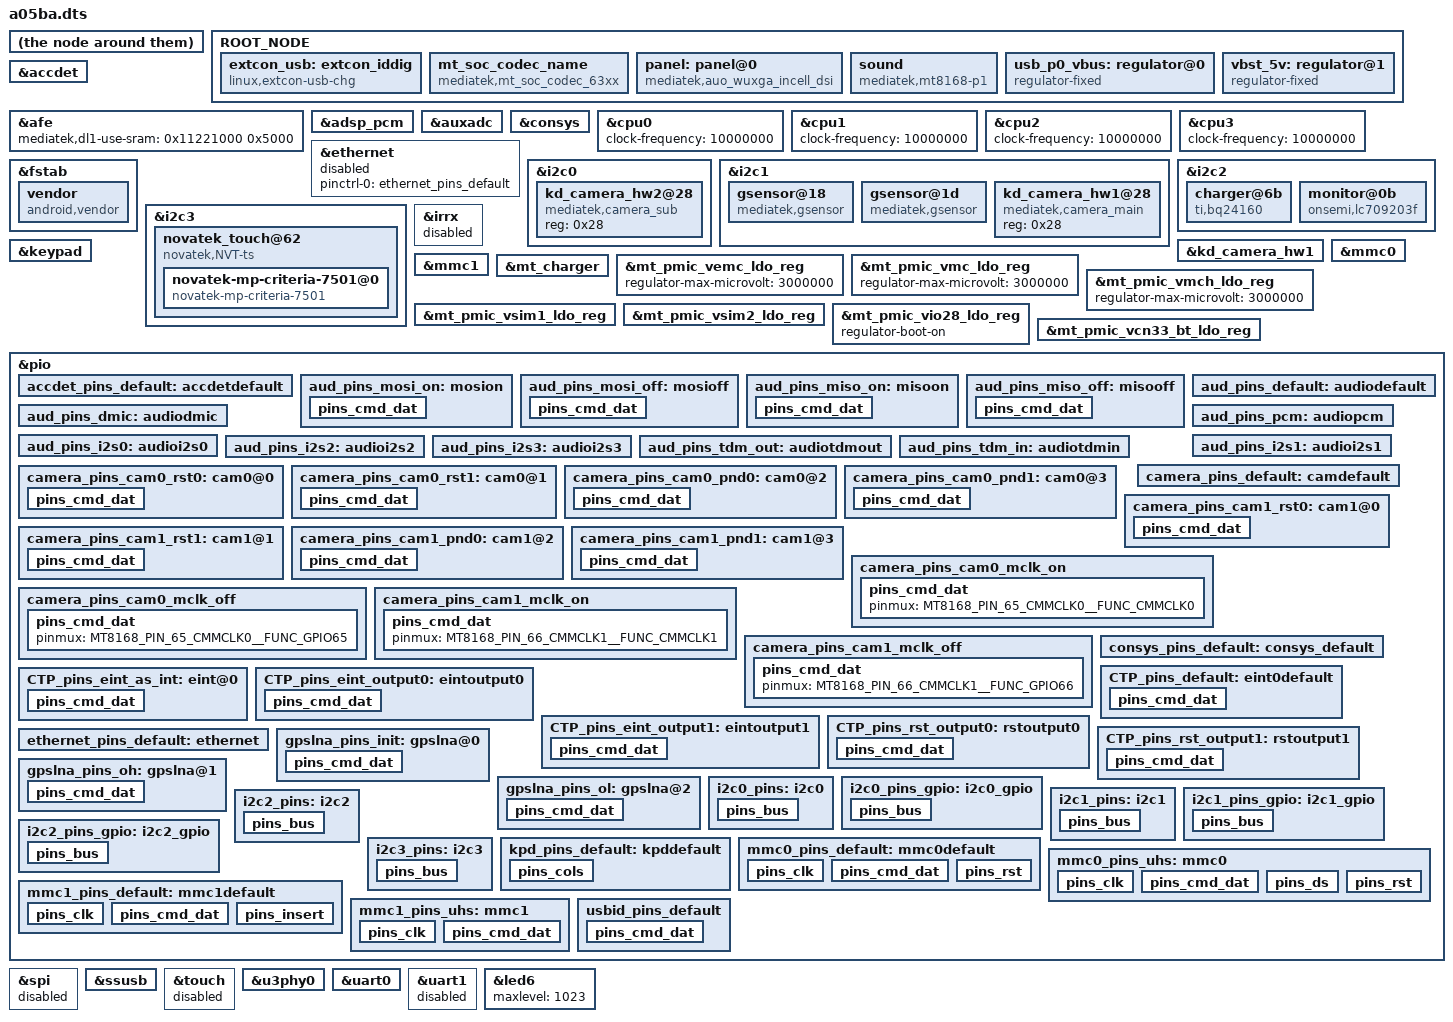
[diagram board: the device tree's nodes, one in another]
/*
 * Copyright (c) 2018 MediaTek Inc.
 *
 * This program is free software; you can redistribute it and/or modify
 * it under the terms of the GNU General Public License version 2 as
 * published by the Free Software Foundation.
 *
 * This program is distributed in the hope that it will be useful,
 * MERCHANTABILITY or FITNESS FOR A PARTICULAR PURPOSE.  See the
 * GNU General Public License for more details.
 */

#include <generated/autoconf.h>
/dts-v1/;

/plugin/;
#include <dt-bindings/clock/mt8168-clk.h>
#include <dt-bindings/interrupt-controller/irq.h>
#include <dt-bindings/interrupt-controller/arm-gic.h>
#include <dt-bindings/pinctrl/mt8168-pinfunc.h>
#include <dt-bindings/gpio/gpio.h>
#include <dt-bindings/phy/phy.h>
#define ROOT_NODE &odm

ROOT_NODE {
	extcon_usb: extcon_iddig {
		compatible = "linux,extcon-usb-chg";
		id-gpio = <&pio 17 GPIO_ACTIVE_HIGH>;
		pinctrl-names = "default";
		pinctrl-0 = <&usbid_pins_default>;
	};

	mt_soc_codec_name: mt_soc_codec_name {
		compatible = "mediatek,mt_soc_codec_63xx";
		use_hp_depop_flow = <0>; /* select 1: use, 0: not use */
		use_ul_260k = <0>; /* select 1: use, 0: not use */
	};

	panel: panel@0 {
		compatible = "mediatek,auo_wuxga_incell_dsi";
		gpio_lcd_rst = <&pio 20 0>;
		gpio_lcd_pwr = <&pio 127 0>;
		gpio_lcd_pwr2 = <&pio 122 0>;
		gpio_lcd_bl_en = <&pio 119 0>;
		reg-lcm-supply = <&mt_pmic_vsim1_ldo_reg>;
	};

	sound: sound {
		compatible = "mediatek,mt8168-p1";
		mediatek,platform = <&afe>;
		mediatek,adsp-platform = <&adsp_pcm>;
		pinctrl-names = "aud_mosi_on",
			"aud_mosi_off",
			"aud_miso_on",
			"aud_miso_off",
			"default",
			"aud_dmic",
			"aud_pcm",
			"aud_i2s0",
			"aud_i2s1",
			"aud_i2s2",
			"aud_i2s3",
			"aud_tdm_out",
			"aud_tdm_in";
		pinctrl-0 = <&aud_pins_mosi_on>;
		pinctrl-1 = <&aud_pins_mosi_off>;
		pinctrl-2 = <&aud_pins_miso_on>;
		pinctrl-3 = <&aud_pins_miso_off>;
		pinctrl-4 = <&aud_pins_default>;
		pinctrl-5 = <&aud_pins_dmic>;
		pinctrl-6 = <&aud_pins_pcm>;
		pinctrl-7 = <&aud_pins_i2s0>;
		pinctrl-8 = <&aud_pins_i2s1>;
		pinctrl-9 = <&aud_pins_i2s2>;
		pinctrl-10 = <&aud_pins_i2s3>;
		pinctrl-11 = <&aud_pins_tdm_out>;
		pinctrl-12 = <&aud_pins_tdm_in>;
		ext-amp1-gpio = <&pio 120 0>;
		ext-amp1en-gpio = <&pio 121 0>;
		/*ext-amp2-gpio = <&pio 69 0>;*/
		status = "okay";
	};

	usb_p0_vbus: regulator@0 {
		compatible = "regulator-fixed";
		regulator-name = "vbus";
		regulator-min-microvolt = <5000000>;
		regulator-max-microvolt = <5000000>;
		gpio = <&pio 16 GPIO_ACTIVE_HIGH>;
		enable-active-high;
	};

	vbst_5v: regulator@1 {
		compatible = "regulator-fixed";
		regulator-name = "vbst_5v";
		regulator-min-microvolt = <5000000>;
		regulator-max-microvolt = <5000000>;
		gpio = <&pio 18 GPIO_ACTIVE_HIGH>;
		enable-active-high;
	};
};

&accdet {
	accdet-mic-vol = <6>;
	headset-mode-setting = <0x500 0x500 1 0x1f0 0x800 0x800 0x20 0x44>;
	accdet-plugout-debounce = <1>;
	accdet-mic-mode = <1>;
	headset-eint-level-pol = <8>;
	/*headset-eint-level-pol = <4>;*/
	headset-three-key-threshold = <0 80 220 400>;
	headset-three-key-threshold-CDD = <0 121 192 600>;
	headset-four-key-threshold = <0 100 170 250 420>;
	pinctrl-names = "default", "state_eint_as_int";
	pinctrl-0 = <&accdet_pins_default>;
/*	pinctrl-1 = <&accdet_pins_eint_as_int>;*/
	status = "okay";
};

&afe {
	mediatek,dl1-use-sram = <0x11221000 0x5000>;
	status = "okay";
};

&adsp_pcm {
	status = "okay";
};

&auxadc {
	status = "okay";
};

&consys {
	pinctrl-names = "default", "gps_lna_state_init",
			"gps_lna_state_oh", "gps_lna_state_ol";
	pinctrl-0 = <&consys_pins_default>;
	pinctrl-1 = <&gpslna_pins_init>;
	pinctrl-2 = <&gpslna_pins_oh>;
	pinctrl-3 = <&gpslna_pins_ol>;
	status = "okay";
};

&cpu0 {
	clock-frequency = <10000000>;
};

&cpu1 {
	clock-frequency = <10000000>;
};

&cpu2 {
	clock-frequency = <10000000>;
};

&cpu3 {
	clock-frequency = <10000000>;
};

&ethernet {
	status = "disabled";
	pinctrl-names = "default";
	pinctrl-0 = <&ethernet_pins_default>;
};

&fstab {
	vendor {
		compatible = "android,vendor";
		dev = "/dev/block/platform/soc/11230000.mmc/by-name/vendor";
		type = "ext4";
		mnt_flags = "ro";
		fsmgr_flags = "wait,avb";
	};
};

&i2c0 {
	pinctrl-names = "default","gpio";
	pinctrl-0 = <&i2c0_pins>;
	pinctrl-1 = <&i2c0_pins_gpio>;
	clock-frequency = <370000>;
	status = "okay";
	scl-gpio = <&pio 58 0>;
	sda-gpio = <&pio 57 0>;

	kd_camera_hw2@28 {
		compatible = "mediatek,camera_sub";
		#address-cells = <1>;
		#size-cells = <0>;
		reg = <0x28>;
	};
};

&i2c1 {
	pinctrl-names = "default","gpio";
	pinctrl-0 = <&i2c1_pins>;
	pinctrl-1 = <&i2c1_pins_gpio>;
	clock-frequency = <370000>;
	status = "okay";
	scl-gpio = <&pio 60 0>;
	sda-gpio = <&pio 59 0>;

	gsensor@18 {
		compatible = "mediatek,gsensor";
		#address-cells = <1>;
		#size-cells = <0>;
		reg = <0x18>;
		status = "okay";
		i2c_num = <1>;
		i2c_addr = <0x18 0 0 0>;
		direction = <3>;
		power_id = <0xffff>;
		power_vol = <0>;
		firlen = <0>;
		is_batch_supported = <0>;
	};

	gsensor@1d {
		compatible = "mediatek,gsensor";
		#address-cells = <1>;
		#size-cells = <0>;
		reg = <0x1d>;
		status = "okay";
		i2c_num = <1>;
		i2c_addr = <0x1d 0 0 0>;
		direction = <2>;
		power_id = <0xffff>;
		power_vol = <0>;
		firlen = <0>;
		is_batch_supported = <0>;
	};

	kd_camera_hw1@28 {
		compatible = "mediatek,camera_main";
		#address-cells = <1>;
		#size-cells = <0>;
		reg = <0x28>;
	};
};

&i2c2 {
	pinctrl-names = "default","gpio";
	pinctrl-0 = <&i2c2_pins>;
	pinctrl-1 = <&i2c2_pins_gpio>;
	clock-frequency = <370000>;
	status = "okay";
	scl-gpio = <&pio 62 0>;
	sda-gpio = <&pio 61 0>;

	charger@6b {
		compatible = "ti,bq24160";
		#address-cells = <1>;
		#size-cells = <0>;
		reg      = <0x6b>;
		ena-gpio = <&pio 125 0>;
		/*acdet-gpio = <&pio 39 0>;*/
		/*usbdet-gpio = <&pio 40 0>;*/
	};

	monitor@0b {
		compatible = "onsemi,lc709203f";
		#address-cells = <1>;
		#size-cells = <0>;
		reg      = <0x0b>;
		irq-gpio = <&pio 67 0>;
	};
};

&i2c3 {
	pinctrl-names = "default";
	pinctrl-0 = <&i2c3_pins>;
	clock-frequency = <370000>;
	status = "okay";

	novatek_touch@62 {
		compatible = "novatek,NVT-ts";
		#address-cells = <1>;
		#size-cells = <0>;
		reg = <0x62>;
		novatek,irq-gpio = <&pio 78 0>;
		novatek,pen-support;
		novatek,wgp-stylus;

		novatek,mp-support-dt;

		novatek-mp-criteria-7501@0 {
			#address-cells = <1>;
			#size-cells = <0>;
			compatible = "novatek-mp-criteria-7501";

			/* MP Config */
			IC_X_CFG_SIZE = <32>;
			IC_Y_CFG_SIZE = <48>;
			IC_KEY_CFG_SIZE = <4>;
			X_Channel = <32>;
			Y_Channel = <48>;
			AIN_X = <0 1 2 3 4 5 6 7 8 9 10 11 12 13 14 15 16 17 18 19 20 21 22 23 24 25 26 27 28 29 30 31>;
			AIN_Y = <0 1 2 3 4 5 6 7 8 9 10 11 12 13 14 15 16 17 18 19 20 21 22 23 24 25 26 27 28 29 30 31 32 33 34 35 36 37 38 39 40 41 42 43 44 45 46 47>;
			AIN_KEY = <0 1 2 0xFF>;

			/* MP Criteria */
			PS_Config_Lmt_Short_Rawdata_P = <
				14008	14008	14008	14008	14008	14008	14008	14008	14008	14008	14008	14008	14008	14008	14008	14008	14008	14008	14008	14008	14008	14008	14008	14008	14008	14008	14008	14008	14008	14008	14008	14008
				14008	14008	14008	14008	14008	14008	14008	14008	14008	14008	14008	14008	14008	14008	14008	14008	14008	14008	14008	14008	14008	14008	14008	14008	14008	14008	14008	14008	14008	14008	14008	14008
				14008	14008	14008	14008	14008	14008	14008	14008	14008	14008	14008	14008	14008	14008	14008	14008	14008	14008	14008	14008	14008	14008	14008	14008	14008	14008	14008	14008	14008	14008	14008	14008
				14008	14008	14008	14008	14008	14008	14008	14008	14008	14008	14008	14008	14008	14008	14008	14008	14008	14008	14008	14008	14008	14008	14008	14008	14008	14008	14008	14008	14008	14008	14008	14008
				14008	14008	14008	14008	14008	14008	14008	14008	14008	14008	14008	14008	14008	14008	14008	14008	14008	14008	14008	14008	14008	14008	14008	14008	14008	14008	14008	14008	14008	14008	14008	14008
				14008	14008	14008	14008	14008	14008	14008	14008	14008	14008	14008	14008	14008	14008	14008	14008	14008	14008	14008	14008	14008	14008	14008	14008	14008	14008	14008	14008	14008	14008	14008	14008
				14008	14008	14008	14008	14008	14008	14008	14008	14008	14008	14008	14008	14008	14008	14008	14008	14008	14008	14008	14008	14008	14008	14008	14008	14008	14008	14008	14008	14008	14008	14008	14008
				14008	14008	14008	14008	14008	14008	14008	14008	14008	14008	14008	14008	14008	14008	14008	14008	14008	14008	14008	14008	14008	14008	14008	14008	14008	14008	14008	14008	14008	14008	14008	14008
				14008	14008	14008	14008	14008	14008	14008	14008	14008	14008	14008	14008	14008	14008	14008	14008	14008	14008	14008	14008	14008	14008	14008	14008	14008	14008	14008	14008	14008	14008	14008	14008
				14008	14008	14008	14008	14008	14008	14008	14008	14008	14008	14008	14008	14008	14008	14008	14008	14008	14008	14008	14008	14008	14008	14008	14008	14008	14008	14008	14008	14008	14008	14008	14008
				14008	14008	14008	14008	14008	14008	14008	14008	14008	14008	14008	14008	14008	14008	14008	14008	14008	14008	14008	14008	14008	14008	14008	14008	14008	14008	14008	14008	14008	14008	14008	14008
				14008	14008	14008	14008	14008	14008	14008	14008	14008	14008	14008	14008	14008	14008	14008	14008	14008	14008	14008	14008	14008	14008	14008	14008	14008	14008	14008	14008	14008	14008	14008	14008
				14008	14008	14008	14008	14008	14008	14008	14008	14008	14008	14008	14008	14008	14008	14008	14008	14008	14008	14008	14008	14008	14008	14008	14008	14008	14008	14008	14008	14008	14008	14008	14008
				14008	14008	14008	14008	14008	14008	14008	14008	14008	14008	14008	14008	14008	14008	14008	14008	14008	14008	14008	14008	14008	14008	14008	14008	14008	14008	14008	14008	14008	14008	14008	14008
				14008	14008	14008	14008	14008	14008	14008	14008	14008	14008	14008	14008	14008	14008	14008	14008	14008	14008	14008	14008	14008	14008	14008	14008	14008	14008	14008	14008	14008	14008	14008	14008
				14008	14008	14008	14008	14008	14008	14008	14008	14008	14008	14008	14008	14008	14008	14008	14008	14008	14008	14008	14008	14008	14008	14008	14008	14008	14008	14008	14008	14008	14008	14008	14008
				14008	14008	14008	14008	14008	14008	14008	14008	14008	14008	14008	14008	14008	14008	14008	14008	14008	14008	14008	14008	14008	14008	14008	14008	14008	14008	14008	14008	14008	14008	14008	14008
				14008	14008	14008	14008	14008	14008	14008	14008	14008	14008	14008	14008	14008	14008	14008	14008	14008	14008	14008	14008	14008	14008	14008	14008	14008	14008	14008	14008	14008	14008	14008	14008
				14008	14008	14008	14008	14008	14008	14008	14008	14008	14008	14008	14008	14008	14008	14008	14008	14008	14008	14008	14008	14008	14008	14008	14008	14008	14008	14008	14008	14008	14008	14008	14008
				14008	14008	14008	14008	14008	14008	14008	14008	14008	14008	14008	14008	14008	14008	14008	14008	14008	14008	14008	14008	14008	14008	14008	14008	14008	14008	14008	14008	14008	14008	14008	14008
				14008	14008	14008	14008	14008	14008	14008	14008	14008	14008	14008	14008	14008	14008	14008	14008	14008	14008	14008	14008	14008	14008	14008	14008	14008	14008	14008	14008	14008	14008	14008	14008
				14008	14008	14008	14008	14008	14008	14008	14008	14008	14008	14008	14008	14008	14008	14008	14008	14008	14008	14008	14008	14008	14008	14008	14008	14008	14008	14008	14008	14008	14008	14008	14008
				14008	14008	14008	14008	14008	14008	14008	14008	14008	14008	14008	14008	14008	14008	14008	14008	14008	14008	14008	14008	14008	14008	14008	14008	14008	14008	14008	14008	14008	14008	14008	14008
				14008	14008	14008	14008	14008	14008	14008	14008	14008	14008	14008	14008	14008	14008	14008	14008	14008	14008	14008	14008	14008	14008	14008	14008	14008	14008	14008	14008	14008	14008	14008	14008
				14008	14008	14008	14008	14008	14008	14008	14008	14008	14008	14008	14008	14008	14008	14008	14008	14008	14008	14008	14008	14008	14008	14008	14008	14008	14008	14008	14008	14008	14008	14008	14008
				14008	14008	14008	14008	14008	14008	14008	14008	14008	14008	14008	14008	14008	14008	14008	14008	14008	14008	14008	14008	14008	14008	14008	14008	14008	14008	14008	14008	14008	14008	14008	14008
				14008	14008	14008	14008	14008	14008	14008	14008	14008	14008	14008	14008	14008	14008	14008	14008	14008	14008	14008	14008	14008	14008	14008	14008	14008	14008	14008	14008	14008	14008	14008	14008
				14008	14008	14008	14008	14008	14008	14008	14008	14008	14008	14008	14008	14008	14008	14008	14008	14008	14008	14008	14008	14008	14008	14008	14008	14008	14008	14008	14008	14008	14008	14008	14008
				14008	14008	14008	14008	14008	14008	14008	14008	14008	14008	14008	14008	14008	14008	14008	14008	14008	14008	14008	14008	14008	14008	14008	14008	14008	14008	14008	14008	14008	14008	14008	14008
				14008	14008	14008	14008	14008	14008	14008	14008	14008	14008	14008	14008	14008	14008	14008	14008	14008	14008	14008	14008	14008	14008	14008	14008	14008	14008	14008	14008	14008	14008	14008	14008
				14008	14008	14008	14008	14008	14008	14008	14008	14008	14008	14008	14008	14008	14008	14008	14008	14008	14008	14008	14008	14008	14008	14008	14008	14008	14008	14008	14008	14008	14008	14008	14008
				14008	14008	14008	14008	14008	14008	14008	14008	14008	14008	14008	14008	14008	14008	14008	14008	14008	14008	14008	14008	14008	14008	14008	14008	14008	14008	14008	14008	14008	14008	14008	14008
				14008	14008	14008	14008	14008	14008	14008	14008	14008	14008	14008	14008	14008	14008	14008	14008	14008	14008	14008	14008	14008	14008	14008	14008	14008	14008	14008	14008	14008	14008	14008	14008
				14008	14008	14008	14008	14008	14008	14008	14008	14008	14008	14008	14008	14008	14008	14008	14008	14008	14008	14008	14008	14008	14008	14008	14008	14008	14008	14008	14008	14008	14008	14008	14008
				14008	14008	14008	14008	14008	14008	14008	14008	14008	14008	14008	14008	14008	14008	14008	14008	14008	14008	14008	14008	14008	14008	14008	14008	14008	14008	14008	14008	14008	14008	14008	14008
				14008	14008	14008	14008	14008	14008	14008	14008	14008	14008	14008	14008	14008	14008	14008	14008	14008	14008	14008	14008	14008	14008	14008	14008	14008	14008	14008	14008	14008	14008	14008	14008
				14008	14008	14008	14008	14008	14008	14008	14008	14008	14008	14008	14008	14008	14008	14008	14008	14008	14008	14008	14008	14008	14008	14008	14008	14008	14008	14008	14008	14008	14008	14008	14008
				14008	14008	14008	14008	14008	14008	14008	14008	14008	14008	14008	14008	14008	14008	14008	14008	14008	14008	14008	14008	14008	14008	14008	14008	14008	14008	14008	14008	14008	14008	14008	14008
				14008	14008	14008	14008	14008	14008	14008	14008	14008	14008	14008	14008	14008	14008	14008	14008	14008	14008	14008	14008	14008	14008	14008	14008	14008	14008	14008	14008	14008	14008	14008	14008
				14008	14008	14008	14008	14008	14008	14008	14008	14008	14008	14008	14008	14008	14008	14008	14008	14008	14008	14008	14008	14008	14008	14008	14008	14008	14008	14008	14008	14008	14008	14008	14008
				14008	14008	14008	14008	14008	14008	14008	14008	14008	14008	14008	14008	14008	14008	14008	14008	14008	14008	14008	14008	14008	14008	14008	14008	14008	14008	14008	14008	14008	14008	14008	14008
				14008	14008	14008	14008	14008	14008	14008	14008	14008	14008	14008	14008	14008	14008	14008	14008	14008	14008	14008	14008	14008	14008	14008	14008	14008	14008	14008	14008	14008	14008	14008	14008
				14008	14008	14008	14008	14008	14008	14008	14008	14008	14008	14008	14008	14008	14008	14008	14008	14008	14008	14008	14008	14008	14008	14008	14008	14008	14008	14008	14008	14008	14008	14008	14008
				14008	14008	14008	14008	14008	14008	14008	14008	14008	14008	14008	14008	14008	14008	14008	14008	14008	14008	14008	14008	14008	14008	14008	14008	14008	14008	14008	14008	14008	14008	14008	14008
				14008	14008	14008	14008	14008	14008	14008	14008	14008	14008	14008	14008	14008	14008	14008	14008	14008	14008	14008	14008	14008	14008	14008	14008	14008	14008	14008	14008	14008	14008	14008	14008
				14008	14008	14008	14008	14008	14008	14008	14008	14008	14008	14008	14008	14008	14008	14008	14008	14008	14008	14008	14008	14008	14008	14008	14008	14008	14008	14008	14008	14008	14008	14008	14008
				14008	14008	14008	14008	14008	14008	14008	14008	14008	14008	14008	14008	14008	14008	14008	14008	14008	14008	14008	14008	14008	14008	14008	14008	14008	14008	14008	14008	14008	14008	14008	14008
				14008	14008	14008	14008	14008	14008	14008	14008	14008	14008	14008	14008	14008	14008	14008	14008	14008	14008	14008	14008	14008	14008	14008	14008	14008	14008	14008	14008	14008	14008	14008	14008
				14008 14008 14008>;

			PS_Config_Lmt_Short_Rawdata_N = <
				10100	10100	10100	10100	10100	10100	10100	10100	10100	10100	10100	10100	10100	10100	10100	10100	10100	10100	10100	10100	10100	10100	10100	10100	10100	10100	10100	10100	10100	10100	10100	10100
				10100	10100	10100	10100	10100	10100	10100	10100	10100	10100	10100	10100	10100	10100	10100	10100	10100	10100	10100	10100	10100	10100	10100	10100	10100	10100	10100	10100	10100	10100	10100	10100
				10100	10100	10100	10100	10100	10100	10100	10100	10100	10100	10100	10100	10100	10100	10100	10100	10100	10100	10100	10100	10100	10100	10100	10100	10100	10100	10100	10100	10100	10100	10100	10100
				10100	10100	10100	10100	10100	10100	10100	10100	10100	10100	10100	10100	10100	10100	10100	10100	10100	10100	10100	10100	10100	10100	10100	10100	10100	10100	10100	10100	10100	10100	10100	10100
				10100	10100	10100	10100	10100	10100	10100	10100	10100	10100	10100	10100	10100	10100	10100	10100	10100	10100	10100	10100	10100	10100	10100	10100	10100	10100	10100	10100	10100	10100	10100	10100
				10100	10100	10100	10100	10100	10100	10100	10100	10100	10100	10100	10100	10100	10100	10100	10100	10100	10100	10100	10100	10100	10100	10100	10100	10100	10100	10100	10100	10100	10100	10100	10100
				10100	10100	10100	10100	10100	10100	10100	10100	10100	10100	10100	10100	10100	10100	10100	10100	10100	10100	10100	10100	10100	10100	10100	10100	10100	10100	10100	10100	10100	10100	10100	10100
				10100	10100	10100	10100	10100	10100	10100	10100	10100	10100	10100	10100	10100	10100	10100	10100	10100	10100	10100	10100	10100	10100	10100	10100	10100	10100	10100	10100	10100	10100	10100	10100
				10100	10100	10100	10100	10100	10100	10100	10100	10100	10100	10100	10100	10100	10100	10100	10100	10100	10100	10100	10100	10100	10100	10100	10100	10100	10100	10100	10100	10100	10100	10100	10100
				10100	10100	10100	10100	10100	10100	10100	10100	10100	10100	10100	10100	10100	10100	10100	10100	10100	10100	10100	10100	10100	10100	10100	10100	10100	10100	10100	10100	10100	10100	10100	10100
				10100	10100	10100	10100	10100	10100	10100	10100	10100	10100	10100	10100	10100	10100	10100	10100	10100	10100	10100	10100	10100	10100	10100	10100	10100	10100	10100	10100	10100	10100	10100	10100
				10100	10100	10100	10100	10100	10100	10100	10100	10100	10100	10100	10100	10100	10100	10100	10100	10100	10100	10100	10100	10100	10100	10100	10100	10100	10100	10100	10100	10100	10100	10100	10100
				10100	10100	10100	10100	10100	10100	10100	10100	10100	10100	10100	10100	10100	10100	10100	10100	10100	10100	10100	10100	10100	10100	10100	10100	10100	10100	10100	10100	10100	10100	10100	10100
				10100	10100	10100	10100	10100	10100	10100	10100	10100	10100	10100	10100	10100	10100	10100	10100	10100	10100	10100	10100	10100	10100	10100	10100	10100	10100	10100	10100	10100	10100	10100	10100
				10100	10100	10100	10100	10100	10100	10100	10100	10100	10100	10100	10100	10100	10100	10100	10100	10100	10100	10100	10100	10100	10100	10100	10100	10100	10100	10100	10100	10100	10100	10100	10100
				10100	10100	10100	10100	10100	10100	10100	10100	10100	10100	10100	10100	10100	10100	10100	10100	10100	10100	10100	10100	10100	10100	10100	10100	10100	10100	10100	10100	10100	10100	10100	10100
				10100	10100	10100	10100	10100	10100	10100	10100	10100	10100	10100	10100	10100	10100	10100	10100	10100	10100	10100	10100	10100	10100	10100	10100	10100	10100	10100	10100	10100	10100	10100	10100
				10100	10100	10100	10100	10100	10100	10100	10100	10100	10100	10100	10100	10100	10100	10100	10100	10100	10100	10100	10100	10100	10100	10100	10100	10100	10100	10100	10100	10100	10100	10100	10100
				10100	10100	10100	10100	10100	10100	10100	10100	10100	10100	10100	10100	10100	10100	10100	10100	10100	10100	10100	10100	10100	10100	10100	10100	10100	10100	10100	10100	10100	10100	10100	10100
				10100	10100	10100	10100	10100	10100	10100	10100	10100	10100	10100	10100	10100	10100	10100	10100	10100	10100	10100	10100	10100	10100	10100	10100	10100	10100	10100	10100	10100	10100	10100	10100
				10100	10100	10100	10100	10100	10100	10100	10100	10100	10100	10100	10100	10100	10100	10100	10100	10100	10100	10100	10100	10100	10100	10100	10100	10100	10100	10100	10100	10100	10100	10100	10100
				10100	10100	10100	10100	10100	10100	10100	10100	10100	10100	10100	10100	10100	10100	10100	10100	10100	10100	10100	10100	10100	10100	10100	10100	10100	10100	10100	10100	10100	10100	10100	10100
				10100	10100	10100	10100	10100	10100	10100	10100	10100	10100	10100	10100	10100	10100	10100	10100	10100	10100	10100	10100	10100	10100	10100	10100	10100	10100	10100	10100	10100	10100	10100	10100
				10100	10100	10100	10100	10100	10100	10100	10100	10100	10100	10100	10100	10100	10100	10100	10100	10100	10100	10100	10100	10100	10100	10100	10100	10100	10100	10100	10100	10100	10100	10100	10100
				10100	10100	10100	10100	10100	10100	10100	10100	10100	10100	10100	10100	10100	10100	10100	10100	10100	10100	10100	10100	10100	10100	10100	10100	10100	10100	10100	10100	10100	10100	10100	10100
				10100	10100	10100	10100	10100	10100	10100	10100	10100	10100	10100	10100	10100	10100	10100	10100	10100	10100	10100	10100	10100	10100	10100	10100	10100	10100	10100	10100	10100	10100	10100	10100
				10100	10100	10100	10100	10100	10100	10100	10100	10100	10100	10100	10100	10100	10100	10100	10100	10100	10100	10100	10100	10100	10100	10100	10100	10100	10100	10100	10100	10100	10100	10100	10100
				10100	10100	10100	10100	10100	10100	10100	10100	10100	10100	10100	10100	10100	10100	10100	10100	10100	10100	10100	10100	10100	10100	10100	10100	10100	10100	10100	10100	10100	10100	10100	10100
				10100	10100	10100	10100	10100	10100	10100	10100	10100	10100	10100	10100	10100	10100	10100	10100	10100	10100	10100	10100	10100	10100	10100	10100	10100	10100	10100	10100	10100	10100	10100	10100
				10100	10100	10100	10100	10100	10100	10100	10100	10100	10100	10100	10100	10100	10100	10100	10100	10100	10100	10100	10100	10100	10100	10100	10100	10100	10100	10100	10100	10100	10100	10100	10100
				10100	10100	10100	10100	10100	10100	10100	10100	10100	10100	10100	10100	10100	10100	10100	10100	10100	10100	10100	10100	10100	10100	10100	10100	10100	10100	10100	10100	10100	10100	10100	10100
				10100	10100	10100	10100	10100	10100	10100	10100	10100	10100	10100	10100	10100	10100	10100	10100	10100	10100	10100	10100	10100	10100	10100	10100	10100	10100	10100	10100	10100	10100	10100	10100
				10100	10100	10100	10100	10100	10100	10100	10100	10100	10100	10100	10100	10100	10100	10100	10100	10100	10100	10100	10100	10100	10100	10100	10100	10100	10100	10100	10100	10100	10100	10100	10100
				10100	10100	10100	10100	10100	10100	10100	10100	10100	10100	10100	10100	10100	10100	10100	10100	10100	10100	10100	10100	10100	10100	10100	10100	10100	10100	10100	10100	10100	10100	10100	10100
				10100	10100	10100	10100	10100	10100	10100	10100	10100	10100	10100	10100	10100	10100	10100	10100	10100	10100	10100	10100	10100	10100	10100	10100	10100	10100	10100	10100	10100	10100	10100	10100
				10100	10100	10100	10100	10100	10100	10100	10100	10100	10100	10100	10100	10100	10100	10100	10100	10100	10100	10100	10100	10100	10100	10100	10100	10100	10100	10100	10100	10100	10100	10100	10100
				10100	10100	10100	10100	10100	10100	10100	10100	10100	10100	10100	10100	10100	10100	10100	10100	10100	10100	10100	10100	10100	10100	10100	10100	10100	10100	10100	10100	10100	10100	10100	10100
				10100	10100	10100	10100	10100	10100	10100	10100	10100	10100	10100	10100	10100	10100	10100	10100	10100	10100	10100	10100	10100	10100	10100	10100	10100	10100	10100	10100	10100	10100	10100	10100
				10100	10100	10100	10100	10100	10100	10100	10100	10100	10100	10100	10100	10100	10100	10100	10100	10100	10100	10100	10100	10100	10100	10100	10100	10100	10100	10100	10100	10100	10100	10100	10100
				10100	10100	10100	10100	10100	10100	10100	10100	10100	10100	10100	10100	10100	10100	10100	10100	10100	10100	10100	10100	10100	10100	10100	10100	10100	10100	10100	10100	10100	10100	10100	10100
				10100	10100	10100	10100	10100	10100	10100	10100	10100	10100	10100	10100	10100	10100	10100	10100	10100	10100	10100	10100	10100	10100	10100	10100	10100	10100	10100	10100	10100	10100	10100	10100
				10100	10100	10100	10100	10100	10100	10100	10100	10100	10100	10100	10100	10100	10100	10100	10100	10100	10100	10100	10100	10100	10100	10100	10100	10100	10100	10100	10100	10100	10100	10100	10100
				10100	10100	10100	10100	10100	10100	10100	10100	10100	10100	10100	10100	10100	10100	10100	10100	10100	10100	10100	10100	10100	10100	10100	10100	10100	10100	10100	10100	10100	10100	10100	10100
				10100	10100	10100	10100	10100	10100	10100	10100	10100	10100	10100	10100	10100	10100	10100	10100	10100	10100	10100	10100	10100	10100	10100	10100	10100	10100	10100	10100	10100	10100	10100	10100
				10100	10100	10100	10100	10100	10100	10100	10100	10100	10100	10100	10100	10100	10100	10100	10100	10100	10100	10100	10100	10100	10100	10100	10100	10100	10100	10100	10100	10100	10100	10100	10100
				10100	10100	10100	10100	10100	10100	10100	10100	10100	10100	10100	10100	10100	10100	10100	10100	10100	10100	10100	10100	10100	10100	10100	10100	10100	10100	10100	10100	10100	10100	10100	10100
				10100	10100	10100	10100	10100	10100	10100	10100	10100	10100	10100	10100	10100	10100	10100	10100	10100	10100	10100	10100	10100	10100	10100	10100	10100	10100	10100	10100	10100	10100	10100	10100
				10100	10100	10100	10100	10100	10100	10100	10100	10100	10100	10100	10100	10100	10100	10100	10100	10100	10100	10100	10100	10100	10100	10100	10100	10100	10100	10100	10100	10100	10100	10100	10100
				10000 10000 10000>;

			PS_Config_Lmt_Open_Rawdata_P = <
				3826	3859	3948	3960	4194	4209	4144	3991	3610	3759	3795	3764	3719	3799	3890	3908	3656	3689	3738	3764	3894	3873	3795	3733	3568	3722	3729	3701	3592	3668	3726	3738
				3781	3844	3872	3949	4032	3997	3974	3906	3502	3602	3637	3644	3689	3745	3763	3750	3635	3659	3728	3774	3760	3704	3686	3634	3460	3539	3598	3616	3565	3609	3619	3574
				3819	3878	3791	3908	4032	4111	4117	4013	3518	3690	3768	3771	3740	3701	3785	3834	3696	3675	3612	3710	3752	3819	3791	3676	3462	3648	3738	3704	3581	3567	3642	3668
				3743	3852	3796	3865	4061	3988	3936	3876	3470	3607	3638	3644	3648	3698	3774	3738	3596	3663	3607	3731	3792	3722	3655	3600	3467	3563	3581	3603	3525	3570	3634	3589
				3823	3889	3836	3738	4015	3992	4057	4027	3455	3620	3731	3770	3773	3752	3718	3150	3704	3721	3627	3558	3721	3711	3768	3712	3462	3563	3689	3746	3607	3585	3574	3036
				3704	3817	3802	3740	3980	4033	3939	3848	3509	3556	3633	3628	3630	3662	3715	3746	3585	3631	3609	3556	3750	3766	3679	3575	3498	3549	3586	3568	3494	3532	3579	3600
				3712	3897	3838	3780	3803	3990	3942	3357	3483	3540	3645	3719	3759	3789	3166	3701	3591	3731	3666	3571	3521	3697	3668	3080	3446	3546	3591	3679	3631	3616	3028	3551
				3801	3771	3766	3753	3805	3949	3973	3854	3451	3610	3598	3635	3631	3659	3687	3691	3679	3610	3579	3557	3519	3719	3710	3613	3427	3600	3589	3589	3472	3512	3553	3551
				3668	3791	3848	3791	3850	3733	3910	3854	3582	3581	3578	3647	3724	3752	3817	3746	3544	3623	3679	3619	3537	3456	3623	3592	3554	3543	3582	3592	3579	3620	3637	3557
				3747	3886	3718	3711	3815	3200	3323	3889	3441	3546	3649	3599	3640	3080	3684	3648	3620	3718	3556	3523	3516	2916	3096	3641	3428	3519	3633	3588	3487	2947	3535	3508
				3613	3747	3731	3787	3852	3809	3700	3851	3532	3675	3614	3575	3644	3745	3815	3753	3536	3585	3561	3619	3570	3501	3430	3578	3519	3645	3571	3575	3484	3591	3675	3567
				3654	3827	3826	3659	3204	3780	3693	3812	3451	3528	3574	3642	3014	3659	3669	3616	3551	3651	3656	3500	2907	3487	3418	3600	3414	3519	3549	3626	2933	3500	3493	3460
				3620	3701	3687	3677	3865	3812	3735	3546	3479	3620	3700	3607	3581	3669	3759	3740	3551	3582	3526	3507	3582	3535	3438	3290	3453	3612	3677	3563	3477	3502	3598	3595
				3595	3738	3771	3543	3736	3735	3707	3546	3469	3530	3551	3333	3647	3619	3672	3603	3512	3598	3598	3357	3465	3446	3423	3287	3439	3494	3540	3311	3521	3493	3504	3423
				3647	3704	3637	3323	3757	3819	3743	3589	3418	3560	3638	3353	3613	3592	3684	3687	3553	3593	3519	3140	3472	3540	3479	3302	3389	3535	3627	3332	3458	3481	3511	3518
				3558	3677	3670	3726	3852	3689	3665	3561	3501	3556	3563	3564	3581	3658	3634	3596	3484	3554	3532	3549	3564	3425	3382	3292	3472	3530	3529	3553	3445	3523	3504	3424
				3621	3732	3120	3596	3714	3698	3736	3595	3458	3505	3035	3652	3707	3621	3605	3602	3581	3600	2973	3479	3438	3420	3467	3341	3423	3484	3018	3640	3564	3459	3486	3421
				3551	3640	3624	3624	3798	3796	3607	3516	3410	3578	3588	3563	3551	3577	3675	3540	3470	3529	3504	3484	3501	3511	3360	3250	3347	3556	3565	3528	3431	3437	3530	3406
				3617	3301	3680	3592	3665	3659	3627	3596	3474	3109	3539	3591	3640	3712	3626	3512	3546	3187	3546	3477	3428	3389	3355	3333	3469	3077	3514	3571	3512	3561	3456	3386
				3498	3526	3589	3564	3700	3747	3719	3467	3365	3368	3609	3575	3551	3558	3581	3578	3413	3400	3479	3438	3444	3456	3442	3222	3340	3318	3586	3553	3402	3428	3431	3424
				3488	3715	3652	3620	3666	3616	3581	3481	3476	3558	3558	3523	3578	3649	3687	3526	3407	3612	3577	3486	3435	3388	3325	3221	3439	3561	3533	3501	3442	3511	3530	3348
				3054	3593	3571	3529	3638	3648	3670	3578	2826	3460	3521	3602	3575	3556	3542	3487	2948	3477	3458	3420	3395	3397	3393	3308	2801	3437	3463	3579	3431	3402	3407	3333
				3486	3588	3648	3589	3697	3614	3542	3444	3476	3570	3582	3551	3522	3585	3627	3593	3430	3479	3546	3514	3444	3389	3316	3190	3432	3542	3585	3526	3376	3444	3484	3430
				3221	3376	3264	3256	3332	3309	3281	3241	3071	3166	3204	3238	3315	3304	3256	3168	3126	3276	3144	3144	3112	3081	3052	2984	3064	3140	3182	3176	3185	3173	3120	3039
				3246	3309	3278	3325	3400	3374	3270	3141	3144	3285	3327	3311	3287	3270	3302	3264	3178	3218	3168	3231	3207	3137	3061	2937	3116	3253	3297	3311	3155	3130	3169	3124
				3183	3316	3350	3238	3347	3311	3257	3187	3144	3173	3214	3224	3259	3350	3298	3186	3138	3192	3252	3119	3123	3089	3038	2959	3081	3171	3187	3199	3089	3213	3162	3047
				3291	3353	3302	3252	3434	3381	3326	3168	3126	3239	3334	3343	3329	3313	3263	3231	3214	3253	3218	3143	3217	3187	3096	2972	3077	3222	3298	3312	3208	3172	3122	3092
				3172	3287	3302	3318	3337	3326	3270	3161	3172	3238	3217	3229	3241	3283	3350	3236	3141	3217	3187	3224	3102	3103	3052	2947	3138	3186	3211	3203	3106	3109	3206	3089
				3278	3396	3344	3270	3354	3410	3325	3225	3113	3227	3290	3353	3364	3348	3305	3200	3238	3290	3246	3186	3127	3199	3144	3001	3068	3186	3269	3320	3208	3222	3164	3050
				3189	3273	3280	3276	3425	3311	3266	3161	3196	3269	3285	3235	3250	3259	3274	3277	3136	3214	3210	3165	3206	3075	3050	2949	3155	3246	3232	3232	3109	3119	3096	3119
				3190	3376	3386	3313	3371	3326	3350	3220	3194	3211	3270	3304	3369	3381	3340	3238	3138	3308	3283	3215	3162	3099	3145	3038	3143	3169	3222	3284	3204	3218	3207	3082
				3271	3280	3270	3248	3378	3395	3256	3168	3103	3294	3315	3302	3256	3262	3250	3207	3214	3204	3217	3183	3144	3183	3035	2962	3084	3266	3287	3249	3129	3119	3110	3017
				3189	3280	3375	3350	3424	3351	3280	3243	3235	3294	3255	3288	3322	3381	3371	3269	3126	3203	3311	3250	3199	3143	3057	3052	3185	3250	3210	3239	3173	3208	3204	3117
				3207	3360	3280	3239	3355	3354	3339	3161	3103	3203	3340	3336	3322	3264	3255	3182	3155	3276	3211	3192	3168	3127	3134	2945	3096	3192	3309	3305	3141	3131	3110	3033
				3186	3284	3283	3339	3473	3404	3290	3180	3131	3336	3343	3271	3306	3326	3374	3295	3157	3197	3214	3278	3232	3180	3092	2965	3117	3302	3297	3234	3130	3175	3197	3126
				3197	3304	3361	3249	3354	3334	3302	3235	3049	3222	3242	3355	3353	3326	3252	3180	3152	3227	3283	3182	3171	3147	3077	3036	3021	3218	3232	3326	3178	3143	3123	3032
				3206	3273	3284	3259	3460	3442	3341	3189	3169	3192	3381	3354	3288	3306	3320	3292	3213	3218	3200	3192	3263	3211	3130	2998	3130	3175	3339	3313	3117	3129	3158	3113
				3180	3280	3305	3336	3365	3329	3283	3200	3084	3108	3246	3259	3382	3354	3319	3185	3161	3215	3242	3263	3166	3151	3099	2984	3039	3091	3239	3249	3201	3173	3124	3045
				3270	3285	3277	3256	3376	3434	3371	3242	3152	3235	3208	3397	3371	3283	3297	3249	3214	3276	3229	3179	3172	3234	3157	3032	3122	3200	3196	3360	3186	3112	3115	3081
				3166	3255	3277	3270	3459	3332	3273	3179	3084	3138	3124	3260	3270	3367	3350	3242	3137	3217	3222	3211	3238	3140	3103	3001	3067	3098	3110	3257	3126	3186	3154	3046
				3276	3348	3276	3246	3371	3347	3365	3263	3095	3208	3243	3215	3403	3360	3277	3220	3253	3276	3280	3206	3158	3152	3176	3060	3096	3179	3211	3194	3206	3172	3091	3032
				3157	3242	3252	3250	3390	3427	3270	3169	3095	3136	3150	3129	3267	3259	3358	3266	3136	3193	3218	3196	3192	3215	3087	3007	3080	3119	3108	3110	3123	3109	3161	3064
				3242	3347	3330	3252	3368	3341	3284	3255	3060	3151	3222	3253	3229	3390	3347	3194	3243	3304	3269	3260	3180	3133	3092	3071	3059	3147	3193	3215	3056	3187	3145	3007
				3150	3227	3239	3227	3372	3355	3350	3173	3067	3152	3151	3157	3143	3257	3253	3278	3162	3185	3192	3203	3172	3162	3148	2989	3056	3133	3131	3109	2986	3108	3092	3075
				3158	3311	3330	3304	3378	3329	3269	3178	3115	3117	3166	3228	3267	3267	3382	3267	3148	3294	3301	3246	3231	3148	3068	2991	3070	3106	3161	3197	3066	3082	3159	3056
				3193	3211	3218	3211	3348	3333	3278	3242	3052	3120	3161	3159	3166	3172	3245	3172	3206	3211	3183	3169	3171	3138	3091	3050	3043	3112	3145	3133	2977	3010	3080	3012
				3152	3221	3292	3294	3437	3343	3256	3166	3117	3168	3122	3166	3235	3291	3253	3285	3140	3187	3290	3280	3218	3197	3084	2982	3091	3127	3116	3155	3043	3082	3047	3066
				3137	3255	3207	3197	3332	3312	3259	3172	3028	3098	3123	3152	3164	3189	3159	3145	3161	3238	3204	3162	3140	3143	3063	2994	3017	3087	3115	3138	2996	3003	2989	2994
				5120 5120 5120>;

			PS_Config_Lmt_Open_Rawdata_N = <
				1639	1654	1692	1697	1797	1804	1776	1710	1547	1611	1626	1613	1594	1628	1667	1675	1567	1581	1602	1613	1669	1660	1626	1600	1529	1595	1598	1586	1539	1572	1597	1602
				1620	1647	1659	1692	1728	1713	1703	1674	1501	1543	1558	1561	1581	1605	1612	1607	1558	1568	1597	1617	1611	1587	1579	1557	1483	1516	1542	1549	1528	1546	1551	1531
				1636	1662	1624	1675	1728	1762	1764	1720	1507	1581	1615	1616	1603	1586	1622	1643	1584	1575	1548	1590	1608	1636	1624	1575	1483	1563	1602	1587	1534	1528	1561	1572
				1604	1651	1627	1656	1740	1709	1687	1661	1487	1546	1559	1561	1563	1585	1617	1602	1541	1570	1546	1599	1625	1595	1566	1543	1486	1527	1534	1544	1510	1530	1557	1538
				1638	1666	1644	1602	1720	1711	1738	1726	1480	1551	1599	1615	1617	1608	1593	1350	1587	1594	1554	1525	1594	1590	1615	1591	1483	1527	1581	1605	1546	1536	1531	1301
				1587	1636	1629	1603	1705	1728	1688	1649	1504	1524	1557	1555	1555	1569	1592	1605	1536	1556	1546	1524	1607	1614	1576	1532	1499	1521	1537	1529	1497	1513	1534	1543
				1591	1670	1645	1620	1630	1710	1689	1438	1492	1517	1562	1594	1611	1624	1357	1586	1539	1599	1571	1530	1509	1584	1572	1320	1477	1519	1539	1576	1556	1549	1297	1522
				1629	1616	1614	1608	1630	1692	1702	1651	1479	1547	1542	1558	1556	1568	1580	1582	1576	1547	1534	1524	1508	1594	1590	1548	1468	1543	1538	1538	1488	1505	1522	1522
				1572	1624	1649	1624	1650	1600	1675	1651	1535	1534	1533	1563	1596	1608	1636	1605	1519	1552	1576	1551	1516	1481	1552	1539	1523	1518	1535	1539	1534	1551	1558	1524
				1606	1665	1593	1590	1635	1371	1424	1666	1474	1519	1564	1542	1560	1320	1579	1563	1551	1593	1524	1510	1507	1249	1327	1560	1469	1508	1557	1537	1494	1263	1515	1503
				1548	1606	1599	1623	1651	1632	1585	1650	1513	1575	1549	1532	1561	1605	1635	1608	1515	1536	1526	1551	1530	1500	1470	1533	1508	1562	1530	1532	1493	1539	1575	1528
				1566	1640	1639	1568	1373	1620	1582	1633	1479	1512	1531	1561	1291	1568	1572	1549	1522	1564	1567	1500	1246	1494	1465	1543	1463	1508	1521	1554	1257	1500	1497	1483
				1551	1586	1580	1576	1656	1633	1600	1519	1491	1551	1585	1546	1534	1572	1611	1603	1522	1535	1511	1503	1535	1515	1473	1410	1480	1548	1576	1527	1490	1501	1542	1540
				1540	1602	1616	1518	1601	1600	1588	1519	1486	1513	1522	1428	1563	1551	1573	1544	1505	1542	1542	1438	1485	1477	1467	1408	1474	1497	1517	1419	1509	1497	1501	1467
				1563	1587	1558	1424	1610	1636	1604	1538	1465	1525	1559	1437	1548	1539	1579	1580	1522	1540	1508	1345	1488	1517	1491	1415	1452	1515	1554	1428	1482	1492	1504	1507
				1525	1576	1573	1597	1651	1581	1570	1526	1500	1524	1527	1527	1534	1567	1557	1541	1493	1523	1513	1521	1527	1468	1449	1411	1488	1513	1512	1522	1476	1510	1501	1467
				1552	1599	1337	1541	1591	1585	1601	1540	1482	1502	1300	1565	1588	1552	1545	1543	1534	1543	1274	1491	1473	1465	1486	1432	1467	1493	1293	1560	1527	1482	1494	1466
				1522	1560	1553	1553	1627	1627	1546	1507	1461	1533	1537	1527	1522	1533	1575	1517	1487	1512	1501	1493	1500	1504	1440	1393	1434	1524	1528	1512	1470	1473	1513	1459
				1550	1414	1577	1539	1570	1568	1554	1541	1489	1332	1516	1539	1560	1591	1554	1505	1519	1366	1519	1490	1469	1452	1438	1428	1486	1318	1506	1530	1505	1526	1481	1451
				1499	1511	1538	1527	1585	1606	1594	1486	1442	1443	1546	1532	1522	1525	1534	1533	1462	1457	1491	1473	1476	1481	1475	1381	1431	1422	1537	1522	1458	1469	1470	1467
				1495	1592	1565	1551	1571	1549	1534	1492	1489	1525	1525	1510	1533	1564	1580	1511	1460	1548	1533	1494	1472	1452	1425	1380	1474	1526	1514	1500	1475	1504	1513	1435
				1309	1540	1530	1512	1559	1563	1573	1533	1211	1483	1509	1543	1532	1524	1518	1494	1263	1490	1482	1465	1455	1456	1454	1417	1200	1473	1484	1534	1470	1458	1460	1428
				1494	1537	1563	1538	1584	1549	1518	1476	1489	1530	1535	1522	1509	1536	1554	1540	1470	1491	1519	1506	1476	1452	1421	1367	1471	1518	1536	1511	1447	1476	1493	1470
				1380	1447	1399	1395	1428	1418	1406	1389	1316	1357	1373	1387	1420	1416	1395	1357	1339	1404	1347	1347	1333	1320	1308	1279	1313	1345	1363	1361	1365	1360	1337	1302
				1391	1418	1405	1425	1457	1446	1401	1346	1347	1408	1426	1419	1408	1401	1415	1399	1362	1379	1357	1384	1374	1344	1312	1258	1335	1394	1413	1419	1352	1341	1358	1339
				1364	1421	1435	1387	1434	1419	1396	1366	1347	1360	1377	1381	1396	1435	1413	1365	1345	1368	1393	1336	1338	1324	1302	1268	1320	1359	1366	1371	1324	1377	1355	1306
				1410	1437	1415	1393	1471	1449	1425	1357	1339	1388	1429	1432	1426	1420	1398	1384	1377	1394	1379	1347	1378	1366	1327	1273	1318	1381	1413	1419	1375	1359	1338	1325
				1359	1408	1415	1422	1430	1425	1401	1354	1359	1387	1378	1384	1389	1407	1435	1387	1346	1378	1366	1381	1329	1330	1308	1263	1345	1365	1376	1372	1331	1332	1374	1324
				1405	1455	1433	1401	1437	1461	1425	1382	1334	1383	1410	1437	1441	1435	1416	1371	1387	1410	1391	1365	1340	1371	1347	1286	1315	1365	1401	1423	1375	1381	1356	1307
				1366	1402	1405	1404	1468	1419	1399	1354	1369	1401	1408	1386	1393	1396	1403	1404	1344	1377	1375	1356	1374	1318	1307	1264	1352	1391	1385	1385	1332	1336	1327	1336
				1367	1447	1451	1420	1444	1425	1435	1380	1369	1376	1401	1416	1444	1449	1431	1387	1345	1417	1407	1378	1355	1328	1348	1302	1347	1358	1381	1407	1373	1379	1374	1321
				1402	1405	1401	1392	1447	1455	1395	1357	1330	1411	1420	1415	1395	1398	1393	1374	1377	1373	1378	1364	1347	1364	1300	1269	1321	1399	1408	1392	1341	1336	1333	1293
				1366	1405	1446	1435	1467	1436	1405	1390	1386	1411	1395	1409	1423	1449	1444	1401	1339	1372	1419	1393	1371	1347	1310	1308	1365	1393	1375	1388	1360	1375	1373	1336
				1374	1440	1405	1388	1438	1437	1431	1354	1330	1372	1431	1429	1423	1399	1395	1363	1352	1404	1376	1368	1357	1340	1343	1262	1327	1368	1418	1416	1346	1342	1333	1300
				1365	1407	1407	1431	1488	1459	1410	1363	1342	1429	1432	1402	1417	1425	1446	1412	1353	1370	1377	1405	1385	1363	1325	1270	1336	1415	1413	1386	1341	1360	1370	1339
				1370	1416	1440	1392	1437	1429	1415	1386	1306	1381	1389	1438	1437	1425	1393	1363	1351	1383	1407	1363	1359	1348	1318	1301	1294	1379	1385	1425	1362	1347	1338	1299
				1374	1402	1407	1396	1483	1475	1432	1366	1358	1368	1449	1437	1409	1417	1423	1411	1377	1379	1371	1368	1398	1376	1341	1285	1341	1360	1431	1420	1336	1341	1353	1334
				1363	1405	1416	1429	1442	1426	1407	1371	1321	1332	1391	1396	1449	1437	1422	1365	1354	1378	1389	1398	1357	1350	1328	1279	1302	1324	1388	1392	1372	1360	1339	1305
				1401	1408	1404	1395	1447	1471	1444	1389	1351	1386	1375	1456	1444	1407	1413	1392	1377	1404	1384	1362	1359	1386	1353	1299	1338	1371	1369	1440	1365	1333	1335	1320
				1357	1395	1404	1401	1482	1428	1402	1362	1321	1345	1339	1397	1401	1443	1435	1389	1344	1378	1381	1376	1387	1345	1330	1286	1314	1327	1333	1396	1339	1365	1351	1305
				1404	1435	1404	1391	1444	1434	1442	1398	1326	1375	1390	1378	1458	1440	1404	1380	1394	1404	1405	1374	1353	1351	1361	1311	1327	1362	1376	1369	1374	1359	1324	1299
				1353	1389	1393	1393	1453	1468	1401	1358	1326	1344	1350	1341	1400	1396	1439	1399	1344	1368	1379	1369	1368	1378	1323	1288	1320	1336	1332	1333	1338	1332	1354	1313
				1389	1434	1427	1393	1443	1432	1407	1395	1311	1350	1381	1394	1384	1453	1434	1369	1390	1416	1401	1397	1363	1342	1325	1316	1311	1348	1368	1378	1309	1366	1348	1288
				1350	1383	1388	1383	1445	1438	1435	1360	1314	1351	1350	1353	1347	1396	1394	1405	1355	1365	1368	1372	1359	1355	1349	1281	1309	1342	1342	1332	1279	1332	1325	1318
				1353	1419	1427	1416	1447	1426	1401	1362	1335	1336	1357	1383	1400	1400	1449	1400	1349	1411	1414	1391	1384	1349	1315	1282	1315	1331	1354	1370	1314	1321	1354	1309
				1368	1376	1379	1376	1435	1428	1405	1389	1308	1337	1354	1354	1357	1359	1390	1359	1374	1376	1364	1358	1359	1345	1324	1307	1304	1333	1348	1342	1276	1290	1320	1291
				1351	1380	1411	1411	1473	1432	1395	1357	1336	1357	1338	1357	1386	1410	1394	1408	1345	1366	1410	1405	1379	1370	1321	1278	1324	1340	1335	1352	1304	1321	1306	1314
				1344	1395	1374	1370	1428	1419	1396	1359	1297	1327	1338	1351	1356	1366	1354	1348	1354	1387	1373	1355	1345	1347	1312	1283	1293	1323	1335	1345	1284	1287	1281	1283
				(-511) (-511) (-511)>;

			PS_Config_Lmt_FW_Rawdata_P = <
				1122	1107	1124	1121	1120	1117	1118	1118	1115	1118	1118	1120	1111	1125	1127	1113	1115	1122	1114	1107	1135	1121	1113	1122	1115	1131	1124	1122	1129	1117	1120	1127
				1122	1135	1120	1125	1114	1127	1120	1124	1113	1121	1110	1131	1111	1113	1122	1127	1122	1128	1125	1115	1128	1115	1118	1114	1122	1117	1122	1125	1118	1120	1118	1120
				1104	1117	1125	1114	1122	1113	1128	1131	1120	1113	1120	1120	1125	1114	1104	1110	1114	1124	1122	1122	1121	1134	1114	1129	1118	1115	1111	1129	1107	1113	1115	1117
				1117	1118	1131	1124	1121	1111	1136	1120	1110	1121	1121	1127	1120	1125	1122	1117	1117	1118	1118	1121	1117	1120	1118	1118	1106	1100	1103	1127	1120	1127	1108	1118
				1131	1117	1114	1113	1117	1122	1107	1122	1122	1117	1120	1124	1115	1120	1108	1106	1117	1120	1127	1111	1125	1120	1134	1120	1118	1118	1129	1121	1122	1120	1129	1117
				1120	1122	1127	1117	1108	1127	1113	1106	1110	1110	1110	1121	1120	1111	1125	1113	1122	1127	1128	1115	1118	1117	1121	1122	1114	1114	1129	1125	1114	1114	1122	1124
				1127	1120	1107	1114	1128	1121	1124	1121	1131	1125	1118	1115	1120	1120	1117	1107	1143	1122	1115	1115	1114	1120	1122	1121	1118	1121	1125	1115	1113	1122	1135	1096
				1120	1125	1120	1121	1127	1120	1125	1107	1121	1111	1118	1117	1111	1117	1108	1117	1122	1120	1113	1125	1121	1121	1117	1114	1120	1129	1121	1108	1120	1124	1114	1125
				1111	1108	1114	1103	1124	1124	1121	1108	1111	1121	1117	1107	1120	1111	1129	1125	1131	1124	1122	1115	1118	1118	1128	1131	1124	1114	1121	1115	1121	1106	1113	1104
				1113	1128	1125	1111	1120	1129	1117	1111	1114	1118	1120	1113	1125	1128	1166	1115	1125	1120	1118	1128	1108	1135	1110	1120	1115	1122	1114	1122	1120	1125	1143	1114
				1114	1124	1115	1117	1132	1114	1114	1117	1125	1115	1129	1121	1121	1127	1110	1110	1117	1117	1127	1121	1132	1124	1121	1118	1113	1127	1124	1118	1122	1124	1111	1120
				1121	1128	1127	1128	1127	1125	1118	1117	1125	1120	1129	1128	1131	1129	1121	1120	1111	1114	1104	1117	1125	1111	1122	1122	1106	1121	1118	1118	1131	1122	1122	1113
				1122	1124	1125	1134	1118	1125	1127	1122	1127	1124	1117	1124	1121	1120	1124	1113	1121	1122	1099	1118	1118	1125	1122	1118	1103	1122	1115	1118	1113	1115	1127	1104
				1129	1113	1129	1152	1117	1118	1125	1122	1124	1107	1114	1117	1141	1124	1113	1121	1107	1108	1115	1160	1131	1124	1131	1118	1132	1127	1124	1114	1164	1129	1122	1120
				1128	1125	1124	1185	1107	1115	1120	1115	1120	1117	1124	1127	1209	1118	1114	1124	1118	1120	1108	1223	1111	1107	1111	1124	1118	1113	1115	1129	1206	1115	1106	1120
				1114	1113	1122	1122	1132	1122	1124	1131	1125	1124	1128	1120	1108	1117	1113	1113	1110	1128	1121	1124	1115	1118	1127	1117	1115	1128	1127	1120	1118	1115	1115	1118
				1129	1115	1118	1117	1143	1111	1117	1118	1120	1124	1125	1121	1128	1117	1121	1121	1114	1111	1125	1124	1163	1128	1111	1117	1113	1110	1125	1110	1115	1110	1121	1114
				1118	1114	1110	1118	1128	1127	1107	1121	1128	1124	1121	1117	1122	1127	1113	1122	1120	1127	1127	1122	1127	1122	1135	1118	1125	1127	1115	1125	1120	1110	1131	1121
				1111	1128	1124	1113	1117	1194	1103	1128	1113	1118	1208	1108	1111	1114	1118	1110	1113	1108	1108	1122	1122	1258	1117	1122	1120	1121	1204	1110	1117	1121	1132	1114
				1103	1121	1111	1125	1113	1141	1127	1128	1125	1131	1138	1118	1117	1117	1120	1114	1120	1122	1129	1104	1131	1134	1122	1115	1127	1125	1139	1125	1122	1118	1111	1114
				1115	1125	1115	1127	1127	1120	1122	1124	1104	1115	1115	1135	1122	1128	1100	1114	1113	1111	1122	1121	1117	1121	1131	1114	1118	1127	1124	1111	1110	1117	1120	1107
				1108	1127	1118	1120	1114	1113	1143	1124	1118	1148	1125	1127	1117	1124	1111	1124	1121	1120	1131	1107	1120	1120	1132	1115	1120	1127	1124	1117	1118	1118	1113	1107
				1127	1118	1129	1106	1120	1117	1111	1113	1124	1104	1121	1117	1114	1125	1110	1125	1114	1108	1125	1125	1121	1110	1129	1115	1103	1120	1108	1117	1107	1114	1114	1113
				1118	1128	1111	1125	1113	1104	1118	1113	1106	1110	1121	1125	1121	1120	1113	1118	1127	1115	1107	1115	1118	1120	1117	1114	1129	1122	1120	1128	1135	1113	1122	1114
				1106	1121	1128	1118	1127	1110	1127	1121	1113	1125	1127	1122	1122	1121	1107	1135	1122	1113	1120	1125	1120	1118	1121	1117	1114	1118	1104	1120	1122	1113	1121	1118
				1107	1106	1128	1108	1117	1117	1117	1117	1118	1117	1127	1111	1107	1118	1108	1115	1115	1111	1121	1107	1113	1134	1110	1117	1117	1113	1122	1121	1121	1129	1122	1111
				1075	1132	1110	1125	1114	1129	1121	1114	1124	1110	1115	1122	1108	1113	1121	1059	1096	1128	1111	1128	1121	1115	1117	1121	1118	1115	1120	1108	1111	1117	1110	1045
				1113	1124	1108	1128	1122	1113	1111	1132	1118	1118	1128	1125	1117	1106	1106	1132	1127	1124	1117	1122	1107	1113	1107	1121	1115	1118	1108	1128	1124	1125	1111	1120
				1135	1078	1125	1113	1104	1125	1113	1113	1108	1121	1129	1135	1099	1114	1047	1113	1114	1055	1128	1118	1131	1118	1114	1121	1113	1122	1122	1117	1108	1118	 992	1113
				1124	1115	1124	1128	1129	1125	1120	1125	1121	1110	1124	1125	1110	1121	1121	1129	1124	1110	1125	1115	1118	1124	1124	1104	1104	1117	1117	1108	1124	1117	1120	1128
				1117	1111	1078	1120	1125	1114	1122	1115	1113	1107	1121	1121	1121	1078	1120	1121	1114	1128	1071	1121	1121	1121	1131	1110	1118	1115	1128	1121	1108	1092	1125	1117
				1113	1121	1069	1115	1111	1131	1127	1118	1115	1103	1127	1124	1108	1059	1127	1120	1125	1117	1059	1120	1113	1121	1103	1108	1114	1125	1121	1107	1101	1047	1110	1124
				1118	1121	1117	1118	1124	1113	1114	1117	1124	1113	1114	1120	1104	1111	1132	1120	1127	1115	1124	1122	1111	1115	1127	1103	1118	1135	1118	1121	1121	1114	1122	1118
				1118	1131	1128	 992	1117	1110	1117	1117	1115	1121	1107	1124	1085	1104	1121	1117	1113	1125	1127	1012	1121	1120	1121	1128	1113	1115	1115	1107	1027	1111	1124	1118
				1117	1122	1122	1129	1114	1118	1120	1122	1114	1124	1115	1122	1114	1115	1120	1103	1106	1128	1117	1113	1113	1114	1131	1115	1120	1117	1120	1106	1114	1115	1127	1118
				1111	1124	1121	1115	1015	1127	1114	1120	1117	1115	1122	1022	1111	1114	1134	1115	1118	1115	1122	1131	 989	1113	1131	1111	1124	1107	1114	1027	1120	1110	1142	1134
				1122	1120	1113	1120	1106	1117	1114	1111	1115	1115	1125	1111	1131	1120	1128	1129	1117	1128	1128	1117	1117	1108	1120	1120	1117	1115	1120	1108	1113	1108	1114	1115
				1117	1138	1122	1111	1125	1125	1114	1117	1104	1128	1118	1120	1127	1106	1120	1127	1117	1118	1114	1111	1129	1120	1121	1120	1114	1121	1120	1121	1110	1121	1111	1111
				1111	1118	1120	1118	1118	1079	1114	1125	1115	1043	1134	1121	1122	1122	1114	1115	1117	1127	1115	1131	1108	1069	1132	1127	1111	1033	1122	1115	1131	1110	1128	1115
				1110	1121	1125	1118	1129	1124	1121	1118	1120	1129	1108	1127	1104	1127	1115	1128	1122	1128	1118	1114	1117	1128	1131	1124	1110	1129	1111	1111	1117	1114	1115	1121
				1125	1128	1124	1120	1124	1120	1117	1118	1114	1122	1122	1134	1113	1120	1113	1125	1113	1129	1120	1108	1118	1122	1100	1117	1114	1136	1110	1125	1118	1121	1129	1110
				1113	1131	1128	1110	1125	1122	1121	1122	1114	1115	1110	1108	1113	1131	1122	1117	1120	1128	1111	1114	1107	1107	1122	1125	1125	1124	1124	1118	1111	1117	1127	1128
				1106	1118	1117	1125	1122	1124	1117	1121	1111	1120	1108	1111	1129	1117	1118	1114	1120	1134	1122	1127	1107	1114	1113	1110	1115	1124	1125	1120	1131	1118	1113	1111
				1110	1122	1122	1113	1134	1125	1041	1122	1005	1121	1120	1121	1111	1128	1129	1114	1114	1114	1124	1099	1120	1124	1059	1124	1026	1127	1117	1114	1117	1108	1118	1117
				1124	1118	1118	1107	1110	1121	1124	1117	1129	1114	1115	1114	1114	1124	1115	1118	1118	1118	1121	1127	1124	1118	1125	1120	1124	1128	1125	1111	1101	1128	1118	1122
				1121	1127	1124	1117	1118	1132	1115	1124	1121	1118	1114	1115	1114	1117	1125	1125	1114	1128	1115	1121	1103	1115	1118	1090	1128	1124	1113	1122	1122	1118	1104	1117
				1118	1118	1125	1125	1132	1114	1117	1110	1110	1122	1111	1118	1117	1115	1117	1113	1120	1127	1121	1115	1120	1122	1127	1114	1118	1121	1118	1121	1117	1107	1113	1127
				1114	1113	1122	1121	1111	1110	1129	1110	1115	1115	1120	1117	1118	1113	1104	1125	1124	1118	1114	1115	1128	1117	1127	1120	1124	1125	1128	1127	1117	1125	1124	1124
				3840 3840 3840>;

			PS_Config_Lmt_FW_Rawdata_N = <
				481	474	481	480	480	478	479	479	478	479	479	480	476	482	483	477	478	481	477	474	486	480	477	481	478	484	481	481	484	478	480	483
				481	486	480	482	477	483	480	481	477	480	475	484	476	477	481	483	481	483	482	478	483	478	479	477	481	478	481	482	479	480	479	480
				473	478	482	477	481	477	483	484	480	477	480	480	482	477	473	475	477	481	481	481	480	486	477	484	479	478	476	484	474	477	478	478
				478	479	484	481	480	476	487	480	475	480	480	483	480	482	481	478	478	479	479	480	478	480	479	479	474	471	472	483	480	483	475	479
				484	478	477	477	478	481	474	481	481	478	480	481	478	480	475	474	478	480	483	476	482	480	486	480	479	479	484	480	481	480	484	478
				480	481	483	478	475	483	477	474	475	475	475	480	480	476	482	477	481	483	483	478	479	478	480	481	477	477	484	482	477	477	481	481
				483	480	474	477	483	480	481	480	484	482	479	478	480	480	478	474	490	481	478	478	477	480	481	480	479	480	482	478	477	481	486	469
				480	482	480	480	483	480	482	474	480	476	479	478	476	478	475	478	481	480	477	482	480	480	478	477	480	484	480	475	480	481	477	482
				476	475	477	472	481	481	480	475	476	480	478	474	480	476	484	482	484	481	481	478	479	479	483	484	481	477	480	478	480	474	477	473
				477	483	482	476	480	484	478	476	477	479	480	477	482	483	499	478	482	480	479	483	475	486	475	480	478	481	477	481	480	482	490	477
				477	481	478	478	485	477	477	478	482	478	484	480	480	483	475	475	478	478	483	480	485	481	480	479	477	483	481	479	481	481	476	480
				480	483	483	483	483	482	479	478	482	480	484	483	484	484	480	480	476	477	473	478	482	476	481	481	474	480	479	479	484	481	481	477
				481	481	482	486	479	482	483	481	483	481	478	481	480	480	481	477	480	481	471	479	479	482	481	479	472	481	478	479	477	478	483	473
				484	477	484	493	478	479	482	481	481	474	477	478	489	481	477	480	474	475	478	497	484	481	484	479	485	483	481	477	499	484	481	480
				483	482	481	508	474	478	480	478	480	478	481	483	518	479	477	481	479	480	475	524	476	474	476	481	479	477	478	484	517	478	474	480
				477	477	481	481	485	481	481	484	482	481	483	480	475	478	477	477	475	483	480	481	478	479	483	478	478	483	483	480	479	478	478	479
				484	478	479	478	490	476	478	479	480	481	482	480	483	478	480	480	477	476	482	481	498	483	476	478	477	475	482	475	478	475	480	477
				479	477	475	479	483	483	474	480	483	481	480	478	481	483	477	481	480	483	483	481	483	481	486	479	482	483	478	482	480	475	484	480
				476	483	481	477	478	511	472	483	477	479	517	475	476	477	479	475	477	475	475	481	481	539	478	481	480	480	516	475	478	480	485	477
				472	480	476	482	477	489	483	483	482	484	487	479	478	478	480	477	480	481	484	473	484	486	481	478	483	482	488	482	481	479	476	477
				478	482	478	483	483	480	481	481	473	478	478	486	481	483	471	477	477	476	481	480	478	480	484	477	479	483	481	476	475	478	480	474
				475	483	479	480	477	477	490	481	479	492	482	483	478	481	476	481	480	480	484	474	480	480	485	478	480	483	481	478	479	479	477	474
				483	479	484	474	480	478	476	477	481	473	480	478	477	482	475	482	477	475	482	482	480	475	484	478	472	480	475	478	474	477	477	477
				479	483	476	482	477	473	479	477	474	475	480	482	480	480	477	479	483	478	474	478	479	480	478	477	484	481	480	483	486	477	481	477
				474	480	483	479	483	475	483	480	477	482	483	481	481	480	474	486	481	477	480	482	480	479	480	478	477	479	473	480	481	477	480	479
				474	474	483	475	478	478	478	478	479	478	483	476	474	479	475	478	478	476	480	474	477	486	475	478	478	477	481	480	480	484	481	476
				460	485	475	482	477	484	480	477	481	475	478	481	475	477	480	454	469	483	476	483	480	478	478	480	479	478	480	475	476	478	475	448
				477	481	475	483	481	477	476	485	479	479	483	482	478	474	474	485	483	481	478	481	474	477	474	480	478	479	475	483	481	482	476	480
				486	462	482	477	473	482	477	477	475	480	484	486	471	477	448	477	477	452	483	479	484	479	477	480	477	481	481	478	475	479	425	477
				481	478	481	483	484	482	480	482	480	475	481	482	475	480	480	484	481	475	482	478	479	481	481	473	473	478	478	475	481	478	480	483
				478	476	462	480	482	477	481	478	477	474	480	480	480	462	480	480	477	483	459	480	480	480	484	475	479	478	483	480	475	468	482	478
				477	480	458	478	476	484	483	479	478	472	483	481	475	454	483	480	482	478	454	480	477	480	472	475	477	482	480	474	472	448	475	481
				479	480	478	479	481	477	477	478	481	477	477	480	473	476	485	480	483	478	481	481	476	478	483	472	479	486	479	480	480	477	481	479
				479	484	483	425	478	475	478	478	478	480	474	481	465	473	480	478	477	482	483	433	480	480	480	483	477	478	478	474	440	476	481	479
				478	481	481	484	477	479	480	481	477	481	478	481	477	478	480	472	474	483	478	477	477	477	484	478	480	478	480	474	477	478	483	479
				476	481	480	478	435	483	477	480	478	478	481	438	476	477	486	478	479	478	481	484	424	477	484	476	481	474	477	440	480	475	489	486
				481	480	477	480	474	478	477	476	478	478	482	476	484	480	483	484	478	483	483	478	478	475	480	480	478	478	480	475	477	475	477	478
				478	487	481	476	482	482	477	478	473	483	479	480	483	474	480	483	478	479	477	476	484	480	480	480	477	480	480	480	475	480	476	476
				476	479	480	479	479	462	477	482	478	447	486	480	481	481	477	478	478	483	478	484	475	458	485	483	476	442	481	478	484	475	483	478
				475	480	482	479	484	481	480	479	480	484	475	483	473	483	478	483	481	483	479	477	478	483	484	481	475	484	476	476	478	477	478	480
				482	483	481	480	481	480	478	479	477	481	481	486	477	480	477	482	477	484	480	475	479	481	471	478	477	487	475	482	479	480	484	475
				477	484	483	475	482	481	480	481	477	478	475	475	477	484	481	478	480	483	476	477	474	474	481	482	482	481	481	479	476	478	483	483
				474	479	478	482	481	481	478	480	476	480	475	476	484	478	479	477	480	486	481	483	474	477	477	475	478	481	482	480	484	479	477	476
				475	481	481	477	486	482	446	481	430	480	480	480	476	483	484	477	477	477	481	471	480	481	454	481	439	483	478	477	478	475	479	478
				481	479	479	474	475	480	481	478	484	477	478	477	477	481	478	479	479	479	480	483	481	479	482	480	481	483	482	476	472	483	479	481
				480	483	481	478	479	485	478	481	480	479	477	478	477	478	482	482	477	483	478	480	472	478	479	467	483	481	477	481	481	479	473	478
				479	479	482	482	485	477	478	475	475	481	476	479	478	478	478	477	480	483	480	478	480	481	483	477	479	480	479	480	478	474	477	483
				477	477	481	480	476	475	484	475	478	478	480	478	479	477	473	482	481	479	477	478	483	478	483	480	481	482	483	483	478	482	481	481
				240 240 240>;

			PS_Config_Lmt_FW_CC_P = <
				158	143	153	153	160	160	158	161	161	162	155	155	154	155	157	162	160	143	153	153	158	158	155	160	160	161	155	154	153	155	155	161
				151	143	150	153	154	153	155	155	158	154	151	151	151	154	155	153	153	144	150	154	154	151	154	155	158	154	151	153	151	153	154	151
				154	153	142	151	151	158	158	160	160	160	157	154	154	153	154	155	154	153	142	151	151	157	157	157	158	158	157	154	153	151	154	154
				153	150	143	150	154	154	153	158	157	158	151	151	151	151	154	155	154	151	143	150	154	154	151	157	157	158	151	150	151	151	153	154
				154	153	153	142	151	153	158	161	157	158	155	157	154	153	153	155	155	153	153	142	151	151	157	160	157	158	154	157	153	151	151	154
				150	151	150	143	151	154	154	155	158	157	154	151	150	151	151	154	151	153	150	143	150	154	154	154	158	157	154	151	150	151	151	153
				151	154	153	153	142	151	153	161	155	157	155	155	155	153	153	153	153	154	153	153	142	151	151	161	154	157	154	154	155	153	151	151
				154	150	151	150	143	151	154	157	154	158	153	154	150	150	151	151	155	150	151	150	143	149	154	157	154	158	153	154	150	149	150	151
				150	151	154	153	153	142	153	155	157	155	153	155	154	155	153	154	151	151	154	153	153	140	151	155	157	154	153	154	153	155	153	153
				154	154	150	151	150	143	153	158	154	154	154	153	154	150	149	151	154	154	150	151	150	143	151	157	154	154	154	153	153	150	149	151
				150	150	151	154	153	153	146	155	160	157	153	153	154	154	155	154	151	150	151	154	151	153	144	155	160	157	151	153	153	153	154	153
				151	153	154	150	151	150	147	154	155	154	151	154	151	154	150	150	153	153	154	150	151	150	146	153	155	155	151	154	151	153	149	150
				151	149	150	150	154	153	157	144	157	160	154	151	151	154	154	155	153	150	150	150	154	151	155	144	157	160	153	151	151	153	153	155
				150	151	153	154	150	151	154	146	160	155	151	150	154	151	153	150	151	151	153	153	149	151	153	146	160	155	151	150	153	151	153	150
				151	151	149	149	151	154	157	155	157	157	155	153	150	151	154	154	153	151	150	149	150	153	155	154	155	157	157	153	150	151	153	153
				150	149	151	153	154	150	155	153	157	158	153	151	150	154	151	154	151	149	150	153	153	149	154	151	157	158	153	151	149	153	151	153
				153	151	151	149	149	151	157	155	155	155	153	154	153	151	151	154	154	151	151	149	149	150	157	154	155	155	153	155	151	150	150	153
				149	150	149	150	153	154	153	154	153	158	155	151	150	150	153	151	150	151	149	150	151	153	151	153	153	157	155	151	150	149	153	151
				154	153	151	151	150	149	154	157	155	155	151	153	154	153	151	151	155	153	151	151	149	149	153	155	155	155	150	153	154	151	149	151
				150	149	150	149	151	153	158	151	153	153	154	154	151	150	150	154	151	149	150	149	150	151	155	151	153	153	154	154	150	150	149	153
				149	154	153	150	151	149	153	153	157	155	153	151	153	154	153	151	150	154	151	151	151	149	151	153	155	155	151	151	151	154	151	150
				153	150	147	150	149	151	155	157	153	153	150	153	154	151	150	150	153	149	149	150	147	150	154	154	153	153	149	153	153	150	149	149
				147	149	153	151	151	151	151	151	158	157	153	151	151	151	154	154	149	149	153	151	150	151	151	151	158	155	153	151	150	151	154	153
				150	150	147	146	149	147	153	154	153	151	147	147	151	153	149	149	151	151	147	146	149	146	151	153	151	151	147	147	150	151	149	147
				151	146	146	151	151	150	153	150	154	157	151	150	150	150	150	153	153	147	147	151	150	149	153	149	153	157	151	151	149	149	149	153
				147	147	150	147	147	149	151	151	155	153	149	147	147	151	153	150	147	147	150	147	146	147	150	150	155	153	149	147	146	150	151	149
				149	151	146	146	153	151	153	153	154	154	153	151	150	150	149	147	147	151	146	147	151	150	151	151	153	154	153	151	150	149	147	147
				149	146	147	150	149	147	151	150	154	155	149	147	147	147	151	153	150	146	147	151	147	146	151	149	154	155	149	147	146	146	150	151
				153	147	151	146	147	153	154	151	153	154	150	153	151	150	147	150	153	147	151	146	146	151	153	151	151	154	150	153	150	150	146	149
				147	149	146	146	150	149	150	151	155	155	151	149	147	147	147	151	149	149	146	147	150	147	149	151	155	154	151	149	146	146	146	150
				147	151	149	150	146	147	155	153	153	153	150	150	153	150	150	150	149	151	149	151	146	146	154	153	153	151	150	150	151	149	150	149
				150	147	147	146	147	150	151	149	151	155	151	151	147	146	147	147	151	147	147	146	147	150	150	149	151	155	151	151	147	146	146	146
				147	146	151	150	151	146	150	154	154	153	149	150	150	151	150	150	149	147	151	150	151	146	150	154	153	153	147	149	149	151	149	150
				149	150	146	146	146	147	153	150	149	151	151	151	147	147	147	147	150	150	147	146	146	147	153	149	149	151	151	150	147	147	146	146
				146	146	146	151	150	151	149	149	143	154	149	149	149	150	151	151	147	147	147	151	150	150	149	149	143	154	150	147	149	149	151	150
				147	149	150	146	146	146	150	153	140	147	146	150	150	151	147	147	147	149	150	147	146	146	150	153	140	147	147	150	149	150	147	146
				150	146	146	146	151	150	154	149	154	139	150	149	147	149	149	153	150	146	147	147	151	150	153	149	154	139	150	149	146	147	149	151
				146	146	147	149	147	149	150	150	149	136	144	146	151	150	150	149	147	147	149	150	146	149	149	150	149	136	143	147	150	149	150	147
				149	149	144	146	147	149	153	153	153	149	139	150	149	147	149	150	150	150	146	146	147	147	153	153	151	147	139	149	147	146	147	149
				147	146	146	147	150	147	151	150	153	144	136	143	146	150	150	151	149	146	147	149	150	146	151	149	151	144	136	143	146	150	149	150
				150	149	149	144	146	146	154	153	151	149	150	139	149	147	147	149	151	149	149	146	146	147	154	151	153	149	150	139	147	147	146	147
				146	147	144	146	149	150	150	151	151	149	144	136	143	146	150	151	146	147	146	146	149	150	149	151	151	149	144	135	142	144	150	149
				151	150	149	149	146	146	149	154	149	149	149	150	138	149	147	149	151	150	149	149	146	146	150	154	149	149	149	150	138	147	147	146
				147	144	147	144	146	149	151	150	146	147	149	144	135	143	146	151	149	146	147	146	146	149	151	150	147	147	149	144	133	142	144	150
				144	150	150	149	149	146	150	150	150	146	147	149	150	138	149	149	146	151	150	147	149	146	149	150	150	146	149	147	149	138	147	147
				150	146	144	146	146	146	151	149	147	144	147	149	144	135	143	149	151	147	146	147	146	146	151	149	149	144	147	147	143	133	142	149
				144	144	150	150	149	149	149	150	150	147	146	147	149	150	138	150	146	146	151	150	147	149	149	149	150	146	144	147	146	149	138	147
				143	147	146	144	147	146	150	151	147	144	144	147	149	144	136	146	144	149	149	146	147	146	150	151	147	146	146	147	147	143	133	144
				314 314 314>;

			PS_Config_Lmt_FW_CC_N = <
				71	64	68	68	71	71	71	72	72	73	70	70	69	70	70	73	71	64	68	68	71	71	70	71	71	72	70	69	68	70	70	72
				68	64	67	68	69	68	70	70	71	69	68	68	68	69	70	68	68	65	67	69	69	68	69	70	71	69	68	68	68	68	69	68
				69	68	63	68	68	71	71	71	71	71	70	69	69	68	69	70	69	68	63	68	68	70	70	70	71	71	70	69	68	68	69	69
				68	67	64	67	69	69	68	71	70	71	68	68	68	68	69	70	69	68	64	67	69	69	68	70	70	71	68	67	68	68	68	69
				69	68	68	63	68	68	71	72	70	71	70	70	69	68	68	70	70	68	68	63	68	68	70	71	70	71	69	70	68	68	68	69
				67	68	67	64	68	69	69	70	71	70	69	68	67	68	68	69	68	68	67	64	67	69	69	69	71	70	69	68	67	68	68	68
				68	69	68	68	63	68	68	72	70	70	70	70	70	68	68	68	68	69	68	68	63	68	68	72	69	70	69	69	70	68	68	68
				69	67	68	67	64	68	69	70	69	71	68	69	67	67	68	68	70	67	68	67	64	66	69	70	69	71	68	69	67	66	67	68
				67	68	69	68	68	63	68	70	70	70	68	70	69	70	68	69	68	68	69	68	68	63	68	70	70	69	68	69	68	70	68	68
				69	69	67	68	67	64	68	71	69	69	69	68	69	67	66	68	69	69	67	68	67	64	68	70	69	69	69	68	68	67	66	68
				67	67	68	69	68	68	65	70	71	70	68	68	69	69	70	69	68	67	68	69	68	68	65	70	71	70	68	68	68	68	69	68
				68	68	69	67	68	67	66	69	70	69	68	69	68	69	67	67	68	68	69	67	68	67	65	68	70	70	68	69	68	68	66	67
				68	66	67	67	69	68	70	65	70	71	69	68	68	69	69	70	68	67	67	67	69	68	70	65	70	71	68	68	68	68	68	70
				67	68	68	69	67	68	69	65	71	70	68	67	69	68	68	67	68	68	68	68	66	68	68	65	71	70	68	67	68	68	68	67
				68	68	66	66	68	69	70	70	70	70	70	68	67	68	69	69	68	68	67	66	67	68	70	69	70	70	70	68	67	68	68	68
				67	66	68	68	69	67	70	68	70	71	68	68	67	69	68	69	68	66	67	68	68	66	69	68	70	71	68	68	66	68	68	68
				68	68	68	66	66	68	70	70	70	70	68	69	68	68	68	69	69	68	68	66	66	67	70	69	70	70	68	70	68	67	67	68
				66	67	66	67	68	69	68	69	68	71	70	68	67	67	68	68	67	68	66	67	68	68	68	68	68	70	70	68	67	66	68	68
				69	68	68	68	67	66	69	70	70	70	68	68	69	68	68	68	70	68	68	68	66	66	68	70	70	70	67	68	69	68	66	68
				67	66	67	66	68	68	71	68	68	68	69	69	68	67	67	69	68	66	67	66	67	68	70	68	68	68	69	69	67	67	66	68
				66	69	68	67	68	66	68	68	70	70	68	68	68	69	68	68	67	69	68	68	68	66	68	68	70	70	68	68	68	69	68	67
				68	67	66	67	66	68	70	70	68	68	67	68	69	68	67	67	68	66	66	67	66	67	69	69	68	68	66	68	68	67	66	66
				66	66	68	68	68	68	68	68	71	70	68	68	68	68	69	69	66	66	68	68	67	68	68	68	71	70	68	68	67	68	69	68
				67	67	66	65	66	66	68	69	68	68	66	66	68	68	66	66	68	68	66	65	66	65	68	68	68	68	66	66	67	68	66	66
				68	65	65	68	68	67	68	67	69	70	68	67	67	67	67	68	68	66	66	68	67	66	68	66	68	70	68	68	66	66	66	68
				66	66	67	66	66	66	68	68	70	68	66	66	66	68	68	67	66	66	67	66	65	66	67	67	70	68	66	66	65	67	68	66
				66	68	65	65	68	68	68	68	69	69	68	68	67	67	66	66	66	68	65	66	68	67	68	68	68	69	68	68	67	66	66	66
				66	65	66	67	66	66	68	67	69	70	66	66	66	66	68	68	67	65	66	68	66	65	68	66	69	70	66	66	65	65	67	68
				68	66	68	65	66	68	69	68	68	69	67	68	68	67	66	67	68	66	68	65	65	68	68	68	68	69	67	68	67	67	65	66
				66	66	65	65	67	66	67	68	70	70	68	66	66	66	66	68	66	66	65	66	67	66	66	68	70	69	68	66	65	65	65	67
				66	68	66	67	65	66	70	68	68	68	67	67	68	67	67	67	66	68	66	68	65	65	69	68	68	68	67	67	68	66	67	66
				67	66	66	65	66	67	68	66	68	70	68	68	66	65	66	66	68	66	66	65	66	67	67	66	68	70	68	68	66	65	65	65
				66	65	68	67	68	65	67	69	69	68	66	67	67	68	67	67	66	66	68	67	68	65	67	69	68	68	66	66	66	68	66	67
				66	67	65	65	65	66	68	67	66	68	68	68	66	66	66	66	67	67	66	65	65	66	68	66	66	68	68	67	66	66	65	65
				65	65	65	68	67	68	66	66	64	69	66	66	66	67	68	68	66	66	66	68	67	67	66	66	64	69	67	66	66	66	68	67
				66	66	67	65	65	65	67	68	63	66	65	67	67	68	66	66	66	66	67	66	65	65	67	68	63	66	66	67	66	67	66	65
				67	65	65	65	68	67	69	66	69	62	67	66	66	66	66	68	67	65	66	66	68	67	68	66	69	62	67	66	65	66	66	68
				65	65	66	66	66	66	67	67	66	61	65	65	68	67	67	66	66	66	66	67	65	66	66	67	66	61	64	66	67	66	67	66
				66	66	65	65	66	66	68	68	68	66	62	67	66	66	66	67	67	67	65	65	66	66	68	68	68	66	62	66	66	65	66	66
				66	65	65	66	67	66	68	67	68	65	61	64	65	67	67	68	66	65	66	66	67	65	68	66	68	65	61	64	65	67	66	67
				67	66	66	65	65	65	69	68	68	66	67	62	66	66	66	66	68	66	66	65	65	66	69	68	68	66	67	62	66	66	65	66
				65	66	65	65	66	67	67	68	68	66	65	61	64	65	67	68	65	66	65	65	66	67	66	68	68	66	65	60	63	65	67	66
				68	67	66	66	65	65	66	69	66	66	66	67	62	66	66	66	68	67	66	66	65	65	67	69	66	66	66	67	62	66	66	65
				66	65	66	65	65	66	68	67	65	66	66	65	60	64	65	68	66	65	66	65	65	66	68	67	66	66	66	65	60	63	65	67
				65	67	67	66	66	65	67	67	67	65	66	66	67	62	66	66	65	68	67	66	66	65	66	67	67	65	66	66	66	62	66	66
				67	65	65	65	65	65	68	66	66	65	66	66	65	60	64	66	68	66	65	66	65	65	68	66	66	65	66	66	64	60	63	66
				65	65	67	67	66	66	66	67	67	66	65	66	66	67	62	67	65	65	68	67	66	66	66	66	67	65	65	66	65	66	62	66
				64	66	65	65	66	65	67	68	66	65	65	66	66	65	61	65	65	66	66	65	66	65	67	68	66	65	65	66	66	64	60	65
				0 0 0>;

			PS_Config_Lmt_FW_Diff_P = <
				50	50	50	50	50	50	50	50	50	50	50	50	50	50	50	50	50	50	50	50	50	50	50	50	50	50	50	50	50	50	50	50
				50	50	50	50	50	50	50	50	50	50	50	50	50	50	50	50	50	50	50	50	50	50	50	50	50	50	50	50	50	50	50	50
				50	50	50	50	50	50	50	50	50	50	50	50	50	50	50	50	50	50	50	50	50	50	50	50	50	50	50	50	50	50	50	50
				50	50	50	50	50	50	50	50	50	50	50	50	50	50	50	50	50	50	50	50	50	50	50	50	50	50	50	50	50	50	50	50
				50	50	50	50	50	50	50	50	50	50	50	50	50	50	50	50	50	50	50	50	50	50	50	50	50	50	50	50	50	50	50	50
				50	50	50	50	50	50	50	50	50	50	50	50	50	50	50	50	50	50	50	50	50	50	50	50	50	50	50	50	50	50	50	50
				50	50	50	50	50	50	50	50	50	50	50	50	50	50	50	50	50	50	50	50	50	50	50	50	50	50	50	50	50	50	50	50
				50	50	50	50	50	50	50	50	50	50	50	50	50	50	50	50	50	50	50	50	50	50	50	50	50	50	50	50	50	50	50	50
				50	50	50	50	50	50	50	50	50	50	50	50	50	50	50	50	50	50	50	50	50	50	50	50	50	50	50	50	50	50	50	50
				50	50	50	50	50	50	50	50	50	50	50	50	50	50	50	50	50	50	50	50	50	50	50	50	50	50	50	50	50	50	50	50
				50	50	50	50	50	50	50	50	50	50	50	50	50	50	50	50	50	50	50	50	50	50	50	50	50	50	50	50	50	50	50	50
				50	50	50	50	50	50	50	50	50	50	50	50	50	50	50	50	50	50	50	50	50	50	50	50	50	50	50	50	50	50	50	50
				50	50	50	50	50	50	50	50	50	50	50	50	50	50	50	50	50	50	50	50	50	50	50	50	50	50	50	50	50	50	50	50
				50	50	50	50	50	50	50	50	50	50	50	50	50	50	50	50	50	50	50	50	50	50	50	50	50	50	50	50	50	50	50	50
				50	50	50	50	50	50	50	50	50	50	50	50	50	50	50	50	50	50	50	50	50	50	50	50	50	50	50	50	50	50	50	50
				50	50	50	50	50	50	50	50	50	50	50	50	50	50	50	50	50	50	50	50	50	50	50	50	50	50	50	50	50	50	50	50
				50	50	50	50	50	50	50	50	50	50	50	50	50	50	50	50	50	50	50	50	50	50	50	50	50	50	50	50	50	50	50	50
				50	50	50	50	50	50	50	50	50	50	50	50	50	50	50	50	50	50	50	50	50	50	50	50	50	50	50	50	50	50	50	50
				50	50	50	50	50	50	50	50	50	50	50	50	50	50	50	50	50	50	50	50	50	50	50	50	50	50	50	50	50	50	50	50
				50	50	50	50	50	50	50	50	50	50	50	50	50	50	50	50	50	50	50	50	50	50	50	50	50	50	50	50	50	50	50	50
				50	50	50	50	50	50	50	50	50	50	50	50	50	50	50	50	50	50	50	50	50	50	50	50	50	50	50	50	50	50	50	50
				50	50	50	50	50	50	50	50	50	50	50	50	50	50	50	50	50	50	50	50	50	50	50	50	50	50	50	50	50	50	50	50
				50	50	50	50	50	50	50	50	50	50	50	50	50	50	50	50	50	50	50	50	50	50	50	50	50	50	50	50	50	50	50	50
				50	50	50	50	50	50	50	50	50	50	50	50	50	50	50	50	50	50	50	50	50	50	50	50	50	50	50	50	50	50	50	50
				50	50	50	50	50	50	50	50	50	50	50	50	50	50	50	50	50	50	50	50	50	50	50	50	50	50	50	50	50	50	50	50
				50	50	50	50	50	50	50	50	50	50	50	50	50	50	50	50	50	50	50	50	50	50	50	50	50	50	50	50	50	50	50	50
				50	50	50	50	50	50	50	50	50	50	50	50	50	50	50	50	50	50	50	50	50	50	50	50	50	50	50	50	50	50	50	50
				50	50	50	50	50	50	50	50	50	50	50	50	50	50	50	50	50	50	50	50	50	50	50	50	50	50	50	50	50	50	50	50
				50	50	50	50	50	50	50	50	50	50	50	50	50	50	50	50	50	50	50	50	50	50	50	50	50	50	50	50	50	50	50	50
				50	50	50	50	50	50	50	50	50	50	50	50	50	50	50	50	50	50	50	50	50	50	50	50	50	50	50	50	50	50	50	50
				50	50	50	50	50	50	50	50	50	50	50	50	50	50	50	50	50	50	50	50	50	50	50	50	50	50	50	50	50	50	50	50
				50	50	50	50	50	50	50	50	50	50	50	50	50	50	50	50	50	50	50	50	50	50	50	50	50	50	50	50	50	50	50	50
				50	50	50	50	50	50	50	50	50	50	50	50	50	50	50	50	50	50	50	50	50	50	50	50	50	50	50	50	50	50	50	50
				50	50	50	50	50	50	50	50	50	50	50	50	50	50	50	50	50	50	50	50	50	50	50	50	50	50	50	50	50	50	50	50
				50	50	50	50	50	50	50	50	50	50	50	50	50	50	50	50	50	50	50	50	50	50	50	50	50	50	50	50	50	50	50	50
				50	50	50	50	50	50	50	50	50	50	50	50	50	50	50	50	50	50	50	50	50	50	50	50	50	50	50	50	50	50	50	50
				50	50	50	50	50	50	50	50	50	50	50	50	50	50	50	50	50	50	50	50	50	50	50	50	50	50	50	50	50	50	50	50
				50	50	50	50	50	50	50	50	50	50	50	50	50	50	50	50	50	50	50	50	50	50	50	50	50	50	50	50	50	50	50	50
				50	50	50	50	50	50	50	50	50	50	50	50	50	50	50	50	50	50	50	50	50	50	50	50	50	50	50	50	50	50	50	50
				50	50	50	50	50	50	50	50	50	50	50	50	50	50	50	50	50	50	50	50	50	50	50	50	50	50	50	50	50	50	50	50
				50	50	50	50	50	50	50	50	50	50	50	50	50	50	50	50	50	50	50	50	50	50	50	50	50	50	50	50	50	50	50	50
				50	50	50	50	50	50	50	50	50	50	50	50	50	50	50	50	50	50	50	50	50	50	50	50	50	50	50	50	50	50	50	50
				50	50	50	50	50	50	50	50	50	50	50	50	50	50	50	50	50	50	50	50	50	50	50	50	50	50	50	50	50	50	50	50
				50	50	50	50	50	50	50	50	50	50	50	50	50	50	50	50	50	50	50	50	50	50	50	50	50	50	50	50	50	50	50	50
				50	50	50	50	50	50	50	50	50	50	50	50	50	50	50	50	50	50	50	50	50	50	50	50	50	50	50	50	50	50	50	50
				50	50	50	50	50	50	50	50	50	50	50	50	50	50	50	50	50	50	50	50	50	50	50	50	50	50	50	50	50	50	50	50
				50	50	50	50	50	50	50	50	50	50	50	50	50	50	50	50	50	50	50	50	50	50	50	50	50	50	50	50	50	50	50	50
				50	50	50	50	50	50	50	50	50	50	50	50	50	50	50	50	50	50	50	50	50	50	50	50	50	50	50	50	50	50	50	50
				75 75 75>;

			PS_Config_Lmt_FW_Diff_N = <
				(-50)	(-50)	(-50)	(-50)	(-50)	(-50)	(-50)	(-50)	(-50)	(-50)	(-50)	(-50)	(-50)	(-50)	(-50)	(-50)	(-50)	(-50)	(-50)	(-50)	(-50)	(-50)	(-50)	(-50)	(-50)	(-50)	(-50)	(-50)	(-50)	(-50)	(-50)	(-50)
				(-50)	(-50)	(-50)	(-50)	(-50)	(-50)	(-50)	(-50)	(-50)	(-50)	(-50)	(-50)	(-50)	(-50)	(-50)	(-50)	(-50)	(-50)	(-50)	(-50)	(-50)	(-50)	(-50)	(-50)	(-50)	(-50)	(-50)	(-50)	(-50)	(-50)	(-50)	(-50)
				(-50)	(-50)	(-50)	(-50)	(-50)	(-50)	(-50)	(-50)	(-50)	(-50)	(-50)	(-50)	(-50)	(-50)	(-50)	(-50)	(-50)	(-50)	(-50)	(-50)	(-50)	(-50)	(-50)	(-50)	(-50)	(-50)	(-50)	(-50)	(-50)	(-50)	(-50)	(-50)
				(-50)	(-50)	(-50)	(-50)	(-50)	(-50)	(-50)	(-50)	(-50)	(-50)	(-50)	(-50)	(-50)	(-50)	(-50)	(-50)	(-50)	(-50)	(-50)	(-50)	(-50)	(-50)	(-50)	(-50)	(-50)	(-50)	(-50)	(-50)	(-50)	(-50)	(-50)	(-50)
				(-50)	(-50)	(-50)	(-50)	(-50)	(-50)	(-50)	(-50)	(-50)	(-50)	(-50)	(-50)	(-50)	(-50)	(-50)	(-50)	(-50)	(-50)	(-50)	(-50)	(-50)	(-50)	(-50)	(-50)	(-50)	(-50)	(-50)	(-50)	(-50)	(-50)	(-50)	(-50)
				(-50)	(-50)	(-50)	(-50)	(-50)	(-50)	(-50)	(-50)	(-50)	(-50)	(-50)	(-50)	(-50)	(-50)	(-50)	(-50)	(-50)	(-50)	(-50)	(-50)	(-50)	(-50)	(-50)	(-50)	(-50)	(-50)	(-50)	(-50)	(-50)	(-50)	(-50)	(-50)
				(-50)	(-50)	(-50)	(-50)	(-50)	(-50)	(-50)	(-50)	(-50)	(-50)	(-50)	(-50)	(-50)	(-50)	(-50)	(-50)	(-50)	(-50)	(-50)	(-50)	(-50)	(-50)	(-50)	(-50)	(-50)	(-50)	(-50)	(-50)	(-50)	(-50)	(-50)	(-50)
				(-50)	(-50)	(-50)	(-50)	(-50)	(-50)	(-50)	(-50)	(-50)	(-50)	(-50)	(-50)	(-50)	(-50)	(-50)	(-50)	(-50)	(-50)	(-50)	(-50)	(-50)	(-50)	(-50)	(-50)	(-50)	(-50)	(-50)	(-50)	(-50)	(-50)	(-50)	(-50)
				(-50)	(-50)	(-50)	(-50)	(-50)	(-50)	(-50)	(-50)	(-50)	(-50)	(-50)	(-50)	(-50)	(-50)	(-50)	(-50)	(-50)	(-50)	(-50)	(-50)	(-50)	(-50)	(-50)	(-50)	(-50)	(-50)	(-50)	(-50)	(-50)	(-50)	(-50)	(-50)
				(-50)	(-50)	(-50)	(-50)	(-50)	(-50)	(-50)	(-50)	(-50)	(-50)	(-50)	(-50)	(-50)	(-50)	(-50)	(-50)	(-50)	(-50)	(-50)	(-50)	(-50)	(-50)	(-50)	(-50)	(-50)	(-50)	(-50)	(-50)	(-50)	(-50)	(-50)	(-50)
				(-50)	(-50)	(-50)	(-50)	(-50)	(-50)	(-50)	(-50)	(-50)	(-50)	(-50)	(-50)	(-50)	(-50)	(-50)	(-50)	(-50)	(-50)	(-50)	(-50)	(-50)	(-50)	(-50)	(-50)	(-50)	(-50)	(-50)	(-50)	(-50)	(-50)	(-50)	(-50)
				(-50)	(-50)	(-50)	(-50)	(-50)	(-50)	(-50)	(-50)	(-50)	(-50)	(-50)	(-50)	(-50)	(-50)	(-50)	(-50)	(-50)	(-50)	(-50)	(-50)	(-50)	(-50)	(-50)	(-50)	(-50)	(-50)	(-50)	(-50)	(-50)	(-50)	(-50)	(-50)
				(-50)	(-50)	(-50)	(-50)	(-50)	(-50)	(-50)	(-50)	(-50)	(-50)	(-50)	(-50)	(-50)	(-50)	(-50)	(-50)	(-50)	(-50)	(-50)	(-50)	(-50)	(-50)	(-50)	(-50)	(-50)	(-50)	(-50)	(-50)	(-50)	(-50)	(-50)	(-50)
				(-50)	(-50)	(-50)	(-50)	(-50)	(-50)	(-50)	(-50)	(-50)	(-50)	(-50)	(-50)	(-50)	(-50)	(-50)	(-50)	(-50)	(-50)	(-50)	(-50)	(-50)	(-50)	(-50)	(-50)	(-50)	(-50)	(-50)	(-50)	(-50)	(-50)	(-50)	(-50)
				(-50)	(-50)	(-50)	(-50)	(-50)	(-50)	(-50)	(-50)	(-50)	(-50)	(-50)	(-50)	(-50)	(-50)	(-50)	(-50)	(-50)	(-50)	(-50)	(-50)	(-50)	(-50)	(-50)	(-50)	(-50)	(-50)	(-50)	(-50)	(-50)	(-50)	(-50)	(-50)
				(-50)	(-50)	(-50)	(-50)	(-50)	(-50)	(-50)	(-50)	(-50)	(-50)	(-50)	(-50)	(-50)	(-50)	(-50)	(-50)	(-50)	(-50)	(-50)	(-50)	(-50)	(-50)	(-50)	(-50)	(-50)	(-50)	(-50)	(-50)	(-50)	(-50)	(-50)	(-50)
				(-50)	(-50)	(-50)	(-50)	(-50)	(-50)	(-50)	(-50)	(-50)	(-50)	(-50)	(-50)	(-50)	(-50)	(-50)	(-50)	(-50)	(-50)	(-50)	(-50)	(-50)	(-50)	(-50)	(-50)	(-50)	(-50)	(-50)	(-50)	(-50)	(-50)	(-50)	(-50)
				(-50)	(-50)	(-50)	(-50)	(-50)	(-50)	(-50)	(-50)	(-50)	(-50)	(-50)	(-50)	(-50)	(-50)	(-50)	(-50)	(-50)	(-50)	(-50)	(-50)	(-50)	(-50)	(-50)	(-50)	(-50)	(-50)	(-50)	(-50)	(-50)	(-50)	(-50)	(-50)
				(-50)	(-50)	(-50)	(-50)	(-50)	(-50)	(-50)	(-50)	(-50)	(-50)	(-50)	(-50)	(-50)	(-50)	(-50)	(-50)	(-50)	(-50)	(-50)	(-50)	(-50)	(-50)	(-50)	(-50)	(-50)	(-50)	(-50)	(-50)	(-50)	(-50)	(-50)	(-50)
				(-50)	(-50)	(-50)	(-50)	(-50)	(-50)	(-50)	(-50)	(-50)	(-50)	(-50)	(-50)	(-50)	(-50)	(-50)	(-50)	(-50)	(-50)	(-50)	(-50)	(-50)	(-50)	(-50)	(-50)	(-50)	(-50)	(-50)	(-50)	(-50)	(-50)	(-50)	(-50)
				(-50)	(-50)	(-50)	(-50)	(-50)	(-50)	(-50)	(-50)	(-50)	(-50)	(-50)	(-50)	(-50)	(-50)	(-50)	(-50)	(-50)	(-50)	(-50)	(-50)	(-50)	(-50)	(-50)	(-50)	(-50)	(-50)	(-50)	(-50)	(-50)	(-50)	(-50)	(-50)
				(-50)	(-50)	(-50)	(-50)	(-50)	(-50)	(-50)	(-50)	(-50)	(-50)	(-50)	(-50)	(-50)	(-50)	(-50)	(-50)	(-50)	(-50)	(-50)	(-50)	(-50)	(-50)	(-50)	(-50)	(-50)	(-50)	(-50)	(-50)	(-50)	(-50)	(-50)	(-50)
				(-50)	(-50)	(-50)	(-50)	(-50)	(-50)	(-50)	(-50)	(-50)	(-50)	(-50)	(-50)	(-50)	(-50)	(-50)	(-50)	(-50)	(-50)	(-50)	(-50)	(-50)	(-50)	(-50)	(-50)	(-50)	(-50)	(-50)	(-50)	(-50)	(-50)	(-50)	(-50)
				(-50)	(-50)	(-50)	(-50)	(-50)	(-50)	(-50)	(-50)	(-50)	(-50)	(-50)	(-50)	(-50)	(-50)	(-50)	(-50)	(-50)	(-50)	(-50)	(-50)	(-50)	(-50)	(-50)	(-50)	(-50)	(-50)	(-50)	(-50)	(-50)	(-50)	(-50)	(-50)
				(-50)	(-50)	(-50)	(-50)	(-50)	(-50)	(-50)	(-50)	(-50)	(-50)	(-50)	(-50)	(-50)	(-50)	(-50)	(-50)	(-50)	(-50)	(-50)	(-50)	(-50)	(-50)	(-50)	(-50)	(-50)	(-50)	(-50)	(-50)	(-50)	(-50)	(-50)	(-50)
				(-50)	(-50)	(-50)	(-50)	(-50)	(-50)	(-50)	(-50)	(-50)	(-50)	(-50)	(-50)	(-50)	(-50)	(-50)	(-50)	(-50)	(-50)	(-50)	(-50)	(-50)	(-50)	(-50)	(-50)	(-50)	(-50)	(-50)	(-50)	(-50)	(-50)	(-50)	(-50)
				(-50)	(-50)	(-50)	(-50)	(-50)	(-50)	(-50)	(-50)	(-50)	(-50)	(-50)	(-50)	(-50)	(-50)	(-50)	(-50)	(-50)	(-50)	(-50)	(-50)	(-50)	(-50)	(-50)	(-50)	(-50)	(-50)	(-50)	(-50)	(-50)	(-50)	(-50)	(-50)
				(-50)	(-50)	(-50)	(-50)	(-50)	(-50)	(-50)	(-50)	(-50)	(-50)	(-50)	(-50)	(-50)	(-50)	(-50)	(-50)	(-50)	(-50)	(-50)	(-50)	(-50)	(-50)	(-50)	(-50)	(-50)	(-50)	(-50)	(-50)	(-50)	(-50)	(-50)	(-50)
				(-50)	(-50)	(-50)	(-50)	(-50)	(-50)	(-50)	(-50)	(-50)	(-50)	(-50)	(-50)	(-50)	(-50)	(-50)	(-50)	(-50)	(-50)	(-50)	(-50)	(-50)	(-50)	(-50)	(-50)	(-50)	(-50)	(-50)	(-50)	(-50)	(-50)	(-50)	(-50)
				(-50)	(-50)	(-50)	(-50)	(-50)	(-50)	(-50)	(-50)	(-50)	(-50)	(-50)	(-50)	(-50)	(-50)	(-50)	(-50)	(-50)	(-50)	(-50)	(-50)	(-50)	(-50)	(-50)	(-50)	(-50)	(-50)	(-50)	(-50)	(-50)	(-50)	(-50)	(-50)
				(-50)	(-50)	(-50)	(-50)	(-50)	(-50)	(-50)	(-50)	(-50)	(-50)	(-50)	(-50)	(-50)	(-50)	(-50)	(-50)	(-50)	(-50)	(-50)	(-50)	(-50)	(-50)	(-50)	(-50)	(-50)	(-50)	(-50)	(-50)	(-50)	(-50)	(-50)	(-50)
				(-50)	(-50)	(-50)	(-50)	(-50)	(-50)	(-50)	(-50)	(-50)	(-50)	(-50)	(-50)	(-50)	(-50)	(-50)	(-50)	(-50)	(-50)	(-50)	(-50)	(-50)	(-50)	(-50)	(-50)	(-50)	(-50)	(-50)	(-50)	(-50)	(-50)	(-50)	(-50)
				(-50)	(-50)	(-50)	(-50)	(-50)	(-50)	(-50)	(-50)	(-50)	(-50)	(-50)	(-50)	(-50)	(-50)	(-50)	(-50)	(-50)	(-50)	(-50)	(-50)	(-50)	(-50)	(-50)	(-50)	(-50)	(-50)	(-50)	(-50)	(-50)	(-50)	(-50)	(-50)
				(-50)	(-50)	(-50)	(-50)	(-50)	(-50)	(-50)	(-50)	(-50)	(-50)	(-50)	(-50)	(-50)	(-50)	(-50)	(-50)	(-50)	(-50)	(-50)	(-50)	(-50)	(-50)	(-50)	(-50)	(-50)	(-50)	(-50)	(-50)	(-50)	(-50)	(-50)	(-50)
				(-50)	(-50)	(-50)	(-50)	(-50)	(-50)	(-50)	(-50)	(-50)	(-50)	(-50)	(-50)	(-50)	(-50)	(-50)	(-50)	(-50)	(-50)	(-50)	(-50)	(-50)	(-50)	(-50)	(-50)	(-50)	(-50)	(-50)	(-50)	(-50)	(-50)	(-50)	(-50)
				(-50)	(-50)	(-50)	(-50)	(-50)	(-50)	(-50)	(-50)	(-50)	(-50)	(-50)	(-50)	(-50)	(-50)	(-50)	(-50)	(-50)	(-50)	(-50)	(-50)	(-50)	(-50)	(-50)	(-50)	(-50)	(-50)	(-50)	(-50)	(-50)	(-50)	(-50)	(-50)
				(-50)	(-50)	(-50)	(-50)	(-50)	(-50)	(-50)	(-50)	(-50)	(-50)	(-50)	(-50)	(-50)	(-50)	(-50)	(-50)	(-50)	(-50)	(-50)	(-50)	(-50)	(-50)	(-50)	(-50)	(-50)	(-50)	(-50)	(-50)	(-50)	(-50)	(-50)	(-50)
				(-50)	(-50)	(-50)	(-50)	(-50)	(-50)	(-50)	(-50)	(-50)	(-50)	(-50)	(-50)	(-50)	(-50)	(-50)	(-50)	(-50)	(-50)	(-50)	(-50)	(-50)	(-50)	(-50)	(-50)	(-50)	(-50)	(-50)	(-50)	(-50)	(-50)	(-50)	(-50)
				(-50)	(-50)	(-50)	(-50)	(-50)	(-50)	(-50)	(-50)	(-50)	(-50)	(-50)	(-50)	(-50)	(-50)	(-50)	(-50)	(-50)	(-50)	(-50)	(-50)	(-50)	(-50)	(-50)	(-50)	(-50)	(-50)	(-50)	(-50)	(-50)	(-50)	(-50)	(-50)
				(-50)	(-50)	(-50)	(-50)	(-50)	(-50)	(-50)	(-50)	(-50)	(-50)	(-50)	(-50)	(-50)	(-50)	(-50)	(-50)	(-50)	(-50)	(-50)	(-50)	(-50)	(-50)	(-50)	(-50)	(-50)	(-50)	(-50)	(-50)	(-50)	(-50)	(-50)	(-50)
				(-50)	(-50)	(-50)	(-50)	(-50)	(-50)	(-50)	(-50)	(-50)	(-50)	(-50)	(-50)	(-50)	(-50)	(-50)	(-50)	(-50)	(-50)	(-50)	(-50)	(-50)	(-50)	(-50)	(-50)	(-50)	(-50)	(-50)	(-50)	(-50)	(-50)	(-50)	(-50)
				(-50)	(-50)	(-50)	(-50)	(-50)	(-50)	(-50)	(-50)	(-50)	(-50)	(-50)	(-50)	(-50)	(-50)	(-50)	(-50)	(-50)	(-50)	(-50)	(-50)	(-50)	(-50)	(-50)	(-50)	(-50)	(-50)	(-50)	(-50)	(-50)	(-50)	(-50)	(-50)
				(-50)	(-50)	(-50)	(-50)	(-50)	(-50)	(-50)	(-50)	(-50)	(-50)	(-50)	(-50)	(-50)	(-50)	(-50)	(-50)	(-50)	(-50)	(-50)	(-50)	(-50)	(-50)	(-50)	(-50)	(-50)	(-50)	(-50)	(-50)	(-50)	(-50)	(-50)	(-50)
				(-50)	(-50)	(-50)	(-50)	(-50)	(-50)	(-50)	(-50)	(-50)	(-50)	(-50)	(-50)	(-50)	(-50)	(-50)	(-50)	(-50)	(-50)	(-50)	(-50)	(-50)	(-50)	(-50)	(-50)	(-50)	(-50)	(-50)	(-50)	(-50)	(-50)	(-50)	(-50)
				(-50)	(-50)	(-50)	(-50)	(-50)	(-50)	(-50)	(-50)	(-50)	(-50)	(-50)	(-50)	(-50)	(-50)	(-50)	(-50)	(-50)	(-50)	(-50)	(-50)	(-50)	(-50)	(-50)	(-50)	(-50)	(-50)	(-50)	(-50)	(-50)	(-50)	(-50)	(-50)
				(-50)	(-50)	(-50)	(-50)	(-50)	(-50)	(-50)	(-50)	(-50)	(-50)	(-50)	(-50)	(-50)	(-50)	(-50)	(-50)	(-50)	(-50)	(-50)	(-50)	(-50)	(-50)	(-50)	(-50)	(-50)	(-50)	(-50)	(-50)	(-50)	(-50)	(-50)	(-50)
				(-50)	(-50)	(-50)	(-50)	(-50)	(-50)	(-50)	(-50)	(-50)	(-50)	(-50)	(-50)	(-50)	(-50)	(-50)	(-50)	(-50)	(-50)	(-50)	(-50)	(-50)	(-50)	(-50)	(-50)	(-50)	(-50)	(-50)	(-50)	(-50)	(-50)	(-50)	(-50)
				(-50)	(-50)	(-50)	(-50)	(-50)	(-50)	(-50)	(-50)	(-50)	(-50)	(-50)	(-50)	(-50)	(-50)	(-50)	(-50)	(-50)	(-50)	(-50)	(-50)	(-50)	(-50)	(-50)	(-50)	(-50)	(-50)	(-50)	(-50)	(-50)	(-50)	(-50)	(-50)
				(-75) (-75) (-75)>;

			PS_Config_Lmt_PenTipX_FW_Raw_P = <
				380	380	380	380	380	380	380	380	380	380	380	380	380	380	380	380	380	380	380	380	380	380	380	380	380	380	380	380	380	380	380	380
				380	380	380	380	380	380	380	380	380	380	380	380	380	380	380	380	380	380	380	380	380	380	380	380	380	380	380	380	380	380	380	380
				380	380	380	380	380	380	380	380	380	380	380	380	380	380	380	380	380	380	380	380	380	380	380	380	380	380	380	380	380	380	380	380
				380	380	380	380	380	380	380	380	380	380	380	380	380	380	380	380	380	380	380	380	380	380	380	380	380	380	380	380	380	380	380	380
				380	380	380	380	380	380	380	380	380	380	380	380	380	380	380	380	380	380	380	380	380	380	380	380	380	380	380	380	380	380	380	380
				380	380	380	380	380	380	380	380	380	380	380	380	380	380	380	380	380	380	380	380	380	380	380	380	380	380	380	380	380	380	380	380>;

			PS_Config_Lmt_PenTipX_FW_Raw_N = <
				0	0	0	0	0	0	0	0	0	0	0	0	0	0	0	0	0	0	0	0	0	0	0	0	0	0	0	0	0	0	0	0
				0	0	0	0	0	0	0	0	0	0	0	0	0	0	0	0	0	0	0	0	0	0	0	0	0	0	0	0	0	0	0	0
				0	0	0	0	0	0	0	0	0	0	0	0	0	0	0	0	0	0	0	0	0	0	0	0	0	0	0	0	0	0	0	0
				0	0	0	0	0	0	0	0	0	0	0	0	0	0	0	0	0	0	0	0	0	0	0	0	0	0	0	0	0	0	0	0
				0	0	0	0	0	0	0	0	0	0	0	0	0	0	0	0	0	0	0	0	0	0	0	0	0	0	0	0	0	0	0	0
				0	0	0	0	0	0	0	0	0	0	0	0	0	0	0	0	0	0	0	0	0	0	0	0	0	0	0	0	0	0	0	0>;

			PS_Config_Lmt_PenTipY_FW_Raw_P = <
				380	380	380	380
				380	380	380	380
				380	380	380	380
				380	380	380	380
				380	380	380	380
				380	380	380	380
				380	380	380	380
				380	380	380	380
				380	380	380	380
				380	380	380	380
				380	380	380	380
				380	380	380	380
				380	380	380	380
				380	380	380	380
				380	380	380	380
				380	380	380	380
				380	380	380	380
				380	380	380	380
				380	380	380	380
				380	380	380	380
				380	380	380	380
				380	380	380	380
				380	380	380	380
				380	380	380	380
				380	380	380	380
				380	380	380	380
				380	380	380	380
				380	380	380	380
				380	380	380	380
				380	380	380	380
				380	380	380	380
				380	380	380	380
				380	380	380	380
				380	380	380	380
				380	380	380	380
				380	380	380	380
				380	380	380	380
				380	380	380	380
				380	380	380	380
				380	380	380	380
				380	380	380	380
				380	380	380	380
				380	380	380	380
				380	380	380	380
				380	380	380	380
				380	380	380	380
				380	380	380	380
				380	380	380	380>;

			PS_Config_Lmt_PenTipY_FW_Raw_N = <
				0	0	0	0
				0	0	0	0
				0	0	0	0
				0	0	0	0
				0	0	0	0
				0	0	0	0
				0	0	0	0
				0	0	0	0
				0	0	0	0
				0	0	0	0
				0	0	0	0
				0	0	0	0
				0	0	0	0
				0	0	0	0
				0	0	0	0
				0	0	0	0
				0	0	0	0
				0	0	0	0
				0	0	0	0
				0	0	0	0
				0	0	0	0
				0	0	0	0
				0	0	0	0
				0	0	0	0
				0	0	0	0
				0	0	0	0
				0	0	0	0
				0	0	0	0
				0	0	0	0
				0	0	0	0
				0	0	0	0
				0	0	0	0
				0	0	0	0
				0	0	0	0
				0	0	0	0
				0	0	0	0
				0	0	0	0
				0	0	0	0
				0	0	0	0
				0	0	0	0
				0	0	0	0
				0	0	0	0
				0	0	0	0
				0	0	0	0
				0	0	0	0
				0	0	0	0
				0	0	0	0
				0	0	0	0>;

			PS_Config_Lmt_PenRingX_FW_Raw_P = <
				380	380	380	380	380	380	380	380	380	380	380	380	380	380	380	380	380	380	380	380	380	380	380	380	380	380	380	380	380	380	380	380
				380	380	380	380	380	380	380	380	380	380	380	380	380	380	380	380	380	380	380	380	380	380	380	380	380	380	380	380	380	380	380	380
				380	380	380	380	380	380	380	380	380	380	380	380	380	380	380	380	380	380	380	380	380	380	380	380	380	380	380	380	380	380	380	380
				380	380	380	380	380	380	380	380	380	380	380	380	380	380	380	380	380	380	380	380	380	380	380	380	380	380	380	380	380	380	380	380
				380	380	380	380	380	380	380	380	380	380	380	380	380	380	380	380	380	380	380	380	380	380	380	380	380	380	380	380	380	380	380	380
				380	380	380	380	380	380	380	380	380	380	380	380	380	380	380	380	380	380	380	380	380	380	380	380	380	380	380	380	380	380	380	380>;

			PS_Config_Lmt_PenRingX_FW_Raw_N = <
				0	0	0	0	0	0	0	0	0	0	0	0	0	0	0	0	0	0	0	0	0	0	0	0	0	0	0	0	0	0	0	0
				0	0	0	0	0	0	0	0	0	0	0	0	0	0	0	0	0	0	0	0	0	0	0	0	0	0	0	0	0	0	0	0
				0	0	0	0	0	0	0	0	0	0	0	0	0	0	0	0	0	0	0	0	0	0	0	0	0	0	0	0	0	0	0	0
				0	0	0	0	0	0	0	0	0	0	0	0	0	0	0	0	0	0	0	0	0	0	0	0	0	0	0	0	0	0	0	0
				0	0	0	0	0	0	0	0	0	0	0	0	0	0	0	0	0	0	0	0	0	0	0	0	0	0	0	0	0	0	0	0
				0	0	0	0	0	0	0	0	0	0	0	0	0	0	0	0	0	0	0	0	0	0	0	0	0	0	0	0	0	0	0	0>;
				
			PS_Config_Lmt_PenRingY_FW_Raw_P = <
				380	380	380	380
				380	380	380	380
				380	380	380	380
				380	380	380	380
				380	380	380	380
				380	380	380	380
				380	380	380	380
				380	380	380	380
				380	380	380	380
				380	380	380	380
				380	380	380	380
				380	380	380	380
				380	380	380	380
				380	380	380	380
				380	380	380	380
				380	380	380	380
				380	380	380	380
				380	380	380	380
				380	380	380	380
				380	380	380	380
				380	380	380	380
				380	380	380	380
				380	380	380	380
				380	380	380	380
				380	380	380	380
				380	380	380	380
				380	380	380	380
				380	380	380	380
				380	380	380	380
				380	380	380	380
				380	380	380	380
				380	380	380	380
				380	380	380	380
				380	380	380	380
				380	380	380	380
				380	380	380	380
				380	380	380	380
				380	380	380	380
				380	380	380	380
				380	380	380	380
				380	380	380	380
				380	380	380	380
				380	380	380	380
				380	380	380	380
				380	380	380	380
				380	380	380	380
				380	380	380	380
				380	380	380	380>;

			PS_Config_Lmt_PenRingY_FW_Raw_N = <
				0	0	0	0
				0	0	0	0
				0	0	0	0
				0	0	0	0
				0	0	0	0
				0	0	0	0
				0	0	0	0
				0	0	0	0
				0	0	0	0
				0	0	0	0
				0	0	0	0
				0	0	0	0
				0	0	0	0
				0	0	0	0
				0	0	0	0
				0	0	0	0
				0	0	0	0
				0	0	0	0
				0	0	0	0
				0	0	0	0
				0	0	0	0
				0	0	0	0
				0	0	0	0
				0	0	0	0
				0	0	0	0
				0	0	0	0
				0	0	0	0
				0	0	0	0
				0	0	0	0
				0	0	0	0
				0	0	0	0
				0	0	0	0
				0	0	0	0
				0	0	0	0
				0	0	0	0
				0	0	0	0
				0	0	0	0
				0	0	0	0
				0	0	0	0
				0	0	0	0
				0	0	0	0
				0	0	0	0
				0	0	0	0
				0	0	0	0
				0	0	0	0
				0	0	0	0
				0	0	0	0
				0	0	0	0>;

			PS_Config_Lmt_PenTipX_FW_Diff_P = <
				580	580	580	580	580	580	580	580	580	580	580	580	580	580	580	580	580	580	580	580	580	580	580	580	580	580	580	580	580	580	580	580
				580	580	580	580	580	580	580	580	580	580	580	580	580	580	580	580	580	580	580	580	580	580	580	580	580	580	580	580	580	580	580	580
				580	580	580	580	580	580	580	580	580	580	580	580	580	580	580	580	580	580	580	580	580	580	580	580	580	580	580	580	580	580	580	580
				580	580	580	580	580	580	580	580	580	580	580	580	580	580	580	580	580	580	580	580	580	580	580	580	580	580	580	580	580	580	580	580
				580	580	580	580	580	580	580	580	580	580	580	580	580	580	580	580	580	580	580	580	580	580	580	580	580	580	580	580	580	580	580	580
				580	580	580	580	580	580	580	580	580	580	580	580	580	580	580	580	580	580	580	580	580	580	580	580	580	580	580	580	580	580	580	580>;

			PS_Config_Lmt_PenTipX_FW_Diff_N = <
				(-580)	(-580)	(-580)	(-580)	(-580)	(-580)	(-580)	(-580)	(-580)	(-580)	(-580)	(-580)	(-580)	(-580)	(-580)	(-580)	(-580)	(-580)	(-580)	(-580)	(-580)	(-580)	(-580)	(-580)	(-580)	(-580)	(-580)	(-580)	(-580)	(-580)	(-580)	(-580)
				(-580)	(-580)	(-580)	(-580)	(-580)	(-580)	(-580)	(-580)	(-580)	(-580)	(-580)	(-580)	(-580)	(-580)	(-580)	(-580)	(-580)	(-580)	(-580)	(-580)	(-580)	(-580)	(-580)	(-580)	(-580)	(-580)	(-580)	(-580)	(-580)	(-580)	(-580)	(-580)
				(-580)	(-580)	(-580)	(-580)	(-580)	(-580)	(-580)	(-580)	(-580)	(-580)	(-580)	(-580)	(-580)	(-580)	(-580)	(-580)	(-580)	(-580)	(-580)	(-580)	(-580)	(-580)	(-580)	(-580)	(-580)	(-580)	(-580)	(-580)	(-580)	(-580)	(-580)	(-580)
				(-580)	(-580)	(-580)	(-580)	(-580)	(-580)	(-580)	(-580)	(-580)	(-580)	(-580)	(-580)	(-580)	(-580)	(-580)	(-580)	(-580)	(-580)	(-580)	(-580)	(-580)	(-580)	(-580)	(-580)	(-580)	(-580)	(-580)	(-580)	(-580)	(-580)	(-580)	(-580)
				(-580)	(-580)	(-580)	(-580)	(-580)	(-580)	(-580)	(-580)	(-580)	(-580)	(-580)	(-580)	(-580)	(-580)	(-580)	(-580)	(-580)	(-580)	(-580)	(-580)	(-580)	(-580)	(-580)	(-580)	(-580)	(-580)	(-580)	(-580)	(-580)	(-580)	(-580)	(-580)
				(-580)	(-580)	(-580)	(-580)	(-580)	(-580)	(-580)	(-580)	(-580)	(-580)	(-580)	(-580)	(-580)	(-580)	(-580)	(-580)	(-580)	(-580)	(-580)	(-580)	(-580)	(-580)	(-580)	(-580)	(-580)	(-580)	(-580)	(-580)	(-580)	(-580)	(-580)	(-580)>;

			PS_Config_Lmt_PenTipY_FW_Diff_P = <
				580	580	580	580
				580	580	580	580
				580	580	580	580
				580	580	580	580
				580	580	580	580
				580	580	580	580
				580	580	580	580
				580	580	580	580
				580	580	580	580
				580	580	580	580
				580	580	580	580
				580	580	580	580
				580	580	580	580
				580	580	580	580
				580	580	580	580
				580	580	580	580
				580	580	580	580
				580	580	580	580
				580	580	580	580
				580	580	580	580
				580	580	580	580
				580	580	580	580
				580	580	580	580
				580	580	580	580
				580	580	580	580
				580	580	580	580
				580	580	580	580
				580	580	580	580
				580	580	580	580
				580	580	580	580
				580	580	580	580
				580	580	580	580
				580	580	580	580
				580	580	580	580
				580	580	580	580
				580	580	580	580
				580	580	580	580
				580	580	580	580
				580	580	580	580
				580	580	580	580
				580	580	580	580
				580	580	580	580
				580	580	580	580
				580	580	580	580
				580	580	580	580
				580	580	580	580
				580	580	580	580
				580	580	580	580>;

			PS_Config_Lmt_PenTipY_FW_Diff_N = <
				(-580)	(-580)	(-580)	(-580)
				(-580)	(-580)	(-580)	(-580)
				(-580)	(-580)	(-580)	(-580)
				(-580)	(-580)	(-580)	(-580)
				(-580)	(-580)	(-580)	(-580)
				(-580)	(-580)	(-580)	(-580)
				(-580)	(-580)	(-580)	(-580)
				(-580)	(-580)	(-580)	(-580)
				(-580)	(-580)	(-580)	(-580)
				(-580)	(-580)	(-580)	(-580)
				(-580)	(-580)	(-580)	(-580)
				(-580)	(-580)	(-580)	(-580)
				(-580)	(-580)	(-580)	(-580)
				(-580)	(-580)	(-580)	(-580)
				(-580)	(-580)	(-580)	(-580)
				(-580)	(-580)	(-580)	(-580)
				(-580)	(-580)	(-580)	(-580)
				(-580)	(-580)	(-580)	(-580)
				(-580)	(-580)	(-580)	(-580)
				(-580)	(-580)	(-580)	(-580)
				(-580)	(-580)	(-580)	(-580)
				(-580)	(-580)	(-580)	(-580)
				(-580)	(-580)	(-580)	(-580)
				(-580)	(-580)	(-580)	(-580)
				(-580)	(-580)	(-580)	(-580)
				(-580)	(-580)	(-580)	(-580)
				(-580)	(-580)	(-580)	(-580)
				(-580)	(-580)	(-580)	(-580)
				(-580)	(-580)	(-580)	(-580)
				(-580)	(-580)	(-580)	(-580)
				(-580)	(-580)	(-580)	(-580)
				(-580)	(-580)	(-580)	(-580)
				(-580)	(-580)	(-580)	(-580)
				(-580)	(-580)	(-580)	(-580)
				(-580)	(-580)	(-580)	(-580)
				(-580)	(-580)	(-580)	(-580)
				(-580)	(-580)	(-580)	(-580)
				(-580)	(-580)	(-580)	(-580)
				(-580)	(-580)	(-580)	(-580)
				(-580)	(-580)	(-580)	(-580)
				(-580)	(-580)	(-580)	(-580)
				(-580)	(-580)	(-580)	(-580)
				(-580)	(-580)	(-580)	(-580)
				(-580)	(-580)	(-580)	(-580)
				(-580)	(-580)	(-580)	(-580)
				(-580)	(-580)	(-580)	(-580)
				(-580)	(-580)	(-580)	(-580)
				(-580)	(-580)	(-580)	(-580)>;

			PS_Config_Lmt_PenRingX_FW_Diff_P = <
				580	580	580	580	580	580	580	580	580	580	580	580	580	580	580	580	580	580	580	580	580	580	580	580	580	580	580	580	580	580	580	580
				580	580	580	580	580	580	580	580	580	580	580	580	580	580	580	580	580	580	580	580	580	580	580	580	580	580	580	580	580	580	580	580
				580	580	580	580	580	580	580	580	580	580	580	580	580	580	580	580	580	580	580	580	580	580	580	580	580	580	580	580	580	580	580	580
				580	580	580	580	580	580	580	580	580	580	580	580	580	580	580	580	580	580	580	580	580	580	580	580	580	580	580	580	580	580	580	580
				580	580	580	580	580	580	580	580	580	580	580	580	580	580	580	580	580	580	580	580	580	580	580	580	580	580	580	580	580	580	580	580
				580	580	580	580	580	580	580	580	580	580	580	580	580	580	580	580	580	580	580	580	580	580	580	580	580	580	580	580	580	580	580	580>;

			PS_Config_Lmt_PenRingX_FW_Diff_N = <
				(-580)	(-580)	(-580)	(-580)	(-580)	(-580)	(-580)	(-580)	(-580)	(-580)	(-580)	(-580)	(-580)	(-580)	(-580)	(-580)	(-580)	(-580)	(-580)	(-580)	(-580)	(-580)	(-580)	(-580)	(-580)	(-580)	(-580)	(-580)	(-580)	(-580)	(-580)	(-580)
				(-580)	(-580)	(-580)	(-580)	(-580)	(-580)	(-580)	(-580)	(-580)	(-580)	(-580)	(-580)	(-580)	(-580)	(-580)	(-580)	(-580)	(-580)	(-580)	(-580)	(-580)	(-580)	(-580)	(-580)	(-580)	(-580)	(-580)	(-580)	(-580)	(-580)	(-580)	(-580)
				(-580)	(-580)	(-580)	(-580)	(-580)	(-580)	(-580)	(-580)	(-580)	(-580)	(-580)	(-580)	(-580)	(-580)	(-580)	(-580)	(-580)	(-580)	(-580)	(-580)	(-580)	(-580)	(-580)	(-580)	(-580)	(-580)	(-580)	(-580)	(-580)	(-580)	(-580)	(-580)
				(-580)	(-580)	(-580)	(-580)	(-580)	(-580)	(-580)	(-580)	(-580)	(-580)	(-580)	(-580)	(-580)	(-580)	(-580)	(-580)	(-580)	(-580)	(-580)	(-580)	(-580)	(-580)	(-580)	(-580)	(-580)	(-580)	(-580)	(-580)	(-580)	(-580)	(-580)	(-580)
				(-580)	(-580)	(-580)	(-580)	(-580)	(-580)	(-580)	(-580)	(-580)	(-580)	(-580)	(-580)	(-580)	(-580)	(-580)	(-580)	(-580)	(-580)	(-580)	(-580)	(-580)	(-580)	(-580)	(-580)	(-580)	(-580)	(-580)	(-580)	(-580)	(-580)	(-580)	(-580)
				(-580)	(-580)	(-580)	(-580)	(-580)	(-580)	(-580)	(-580)	(-580)	(-580)	(-580)	(-580)	(-580)	(-580)	(-580)	(-580)	(-580)	(-580)	(-580)	(-580)	(-580)	(-580)	(-580)	(-580)	(-580)	(-580)	(-580)	(-580)	(-580)	(-580)	(-580)	(-580)>;

			PS_Config_Lmt_PenRingY_FW_Diff_P = <
				580	580	580	580
				580	580	580	580
				580	580	580	580
				580	580	580	580
				580	580	580	580
				580	580	580	580
				580	580	580	580
				580	580	580	580
				580	580	580	580
				580	580	580	580
				580	580	580	580
				580	580	580	580
				580	580	580	580
				580	580	580	580
				580	580	580	580
				580	580	580	580
				580	580	580	580
				580	580	580	580
				580	580	580	580
				580	580	580	580
				580	580	580	580
				580	580	580	580
				580	580	580	580
				580	580	580	580
				580	580	580	580
				580	580	580	580
				580	580	580	580
				580	580	580	580
				580	580	580	580
				580	580	580	580
				580	580	580	580
				580	580	580	580
				580	580	580	580
				580	580	580	580
				580	580	580	580
				580	580	580	580
				580	580	580	580
				580	580	580	580
				580	580	580	580
				580	580	580	580
				580	580	580	580
				580	580	580	580
				580	580	580	580
				580	580	580	580
				580	580	580	580
				580	580	580	580
				580	580	580	580
				580	580	580	580>;

			PS_Config_Lmt_PenRingY_FW_Diff_N = <
				(-580)	(-580)	(-580)	(-580)
				(-580)	(-580)	(-580)	(-580)
				(-580)	(-580)	(-580)	(-580)
				(-580)	(-580)	(-580)	(-580)
				(-580)	(-580)	(-580)	(-580)
				(-580)	(-580)	(-580)	(-580)
				(-580)	(-580)	(-580)	(-580)
				(-580)	(-580)	(-580)	(-580)
				(-580)	(-580)	(-580)	(-580)
				(-580)	(-580)	(-580)	(-580)
				(-580)	(-580)	(-580)	(-580)
				(-580)	(-580)	(-580)	(-580)
				(-580)	(-580)	(-580)	(-580)
				(-580)	(-580)	(-580)	(-580)
				(-580)	(-580)	(-580)	(-580)
				(-580)	(-580)	(-580)	(-580)
				(-580)	(-580)	(-580)	(-580)
				(-580)	(-580)	(-580)	(-580)
				(-580)	(-580)	(-580)	(-580)
				(-580)	(-580)	(-580)	(-580)
				(-580)	(-580)	(-580)	(-580)
				(-580)	(-580)	(-580)	(-580)
				(-580)	(-580)	(-580)	(-580)
				(-580)	(-580)	(-580)	(-580)
				(-580)	(-580)	(-580)	(-580)
				(-580)	(-580)	(-580)	(-580)
				(-580)	(-580)	(-580)	(-580)
				(-580)	(-580)	(-580)	(-580)
				(-580)	(-580)	(-580)	(-580)
				(-580)	(-580)	(-580)	(-580)
				(-580)	(-580)	(-580)	(-580)
				(-580)	(-580)	(-580)	(-580)
				(-580)	(-580)	(-580)	(-580)
				(-580)	(-580)	(-580)	(-580)
				(-580)	(-580)	(-580)	(-580)
				(-580)	(-580)	(-580)	(-580)
				(-580)	(-580)	(-580)	(-580)
				(-580)	(-580)	(-580)	(-580)
				(-580)	(-580)	(-580)	(-580)
				(-580)	(-580)	(-580)	(-580)
				(-580)	(-580)	(-580)	(-580)
				(-580)	(-580)	(-580)	(-580)
				(-580)	(-580)	(-580)	(-580)
				(-580)	(-580)	(-580)	(-580)
				(-580)	(-580)	(-580)	(-580)
				(-580)	(-580)	(-580)	(-580)
				(-580)	(-580)	(-580)	(-580)
				(-580)	(-580)	(-580)	(-580)>;

			PS_Config_Diff_Test_Frame = <50>;
		};
	};
};

&irrx {
	status = "disabled";
};

&keypad {
	pinctrl-names = "default";
	pinctrl-0 = <&kpd_pins_default>;
	status = "okay";
	mediatek,kpd-key-debounce = <1024>;
	mediatek,kpd-sw-pwrkey = <116>;
	mediatek,kpd-hw-pwrkey = <1>;
	mediatek,kpd-sw-rstkey  = <114>;
	mediatek,kpd-hw-rstkey = <3>;
	mediatek,kpd-use-extend-type = <0>;
	/*HW Keycode [0~3] -> Linux Keycode*/
	mediatek,kpd-hw-map-num = <72>;
	mediatek,kpd-hw-init-map =
			<115 102 0 0 0 0 0 0 0 0 0 0 0
			 0 0 0 0 0 0 0 0 0 0 0 0 0 0 0 0 0 0 0 0 0 0 0 0
			 0 0 0 0 0 0 0 0 0 0 0 0 0 0 0 0 0 0 0 0 0 0 0 0
			 0 0 0 0 0 0 0 0 0 0 0 >;
	mediatek,kpd-pwrkey-eint-gpio = <0>;
	mediatek,kpd-pwkey-gpio-din  = <0>;
	mediatek,kpd-hw-dl-key0 = <0>;
	mediatek,kpd-hw-dl-key1 = <3>;
	mediatek,kpd-hw-dl-key2 = <1>;
	mediatek,kpd-hw-recovery-key = <0>;
	mediatek,kpd-hw-factory-key  = <3>;
};


&kd_camera_hw1 {
	/* main cam power supply */
	vcama-supply = <&mt_pmic_vcama_ldo_reg>;         /* AVDD */
	vcamd-supply = <&mt_pmic_vcamd_ldo_reg>;         /* DVDD */
	vcamio-supply = <&mt_pmic_vcamio_ldo_reg>;       /* DOVDD */

	/* sub cam power supply */
	vcama_sub-supply = <&mt_pmic_vcama_ldo_reg>;         /* AVDD */
	vcamd_sub-supply = <&mt_pmic_vcamd_ldo_reg>;         /* DVDD */
	vcamio_sub-supply = <&mt_pmic_vcamio_ldo_reg>;       /* DOVDD */

	pinctrl-names = "default",
			"cam0_rst0", "cam0_rst1", "cam0_pnd0", "cam0_pnd1",
			"cam1_rst0", "cam1_rst1", "cam1_pnd0", "cam1_pnd1",
			"cam0_mclk_on", "cam0_mclk_off",
			"cam1_mclk_on", "cam1_mclk_off";

	pinctrl-0 = <&camera_pins_default>;
	pinctrl-1 = <&camera_pins_cam0_rst0>;
	pinctrl-2 = <&camera_pins_cam0_rst1>;
	pinctrl-3 = <&camera_pins_cam0_pnd0>;
	pinctrl-4 = <&camera_pins_cam0_pnd1>;
	pinctrl-5 = <&camera_pins_cam1_rst0>;
	pinctrl-6 = <&camera_pins_cam1_rst1>;
	pinctrl-7 = <&camera_pins_cam1_pnd0>;
	pinctrl-8 = <&camera_pins_cam1_pnd1>;
	pinctrl-9 = <&camera_pins_cam0_mclk_on>;
	pinctrl-10 = <&camera_pins_cam0_mclk_off>;
	pinctrl-11 = <&camera_pins_cam1_mclk_on>;
	pinctrl-12 = <&camera_pins_cam1_mclk_off>;

	status = "okay";
};

&mmc0 {
	status = "okay";
	pinctrl-names = "default", "state_uhs";
	pinctrl-0 = <&mmc0_pins_default>;
	pinctrl-1 = <&mmc0_pins_uhs>;
	bus-width = <8>;
	max-frequency = <200000000>;
	cap-mmc-highspeed;
	mmc-hs200-1_8v;
	mmc-hs400-1_8v;
	cap-cqe;
	cap-cqe_dcmd;
	hs400-ds-delay = <0x12012>;
	vmmc-supply = <&mt_pmic_vemc_ldo_reg>;
	vqmmc-supply = <&mt_pmic_vio18_ldo_reg>;
	assigned-clocks = <&topckgen CLK_TOP_MSDC50_0_SEL>;
	assigned-clock-parents = <&topckgen CLK_TOP_MSDCPLL>;
	non-removable;
	no-sd;
	no-sdio;
};

&mmc1 {
	status = "okay";
	pinctrl-names = "default", "state_uhs";
	pinctrl-0 = <&mmc1_pins_default>;
	pinctrl-1 = <&mmc1_pins_uhs>;
	bus-width = <4>;
	max-frequency = <200000000>;
	cap-sd-highspeed;
	sd-uhs-sdr50;
	sd-uhs-sdr104;
	cd-gpios = <&pio 76 GPIO_ACTIVE_LOW>;
	vmmc-supply = <&mt_pmic_vmch_ldo_reg>;
	vqmmc-supply = <&mt_pmic_vmc_ldo_reg>;
	no-mmc;
	no-sdio;
};

&mt_charger {
	extcon = <&extcon_usb>;
	interrupt-parent = <&pio>;
	interrupts = <126 IRQ_TYPE_EDGE_RISING>;
	chgint-gpios = <&pio 126 0>;
	chgled-gpio = <&pio 118 0>;
	acdet-gpio = <&pio 40 0>;
	usbdet-gpio = <&pio 39 0>;
	usbvbus-gpio = <&pio 16 0>;
	status = "okay";
};

&mt_pmic_vemc_ldo_reg {
	regulator-max-microvolt = <3000000>;
};

&mt_pmic_vmc_ldo_reg {
	regulator-max-microvolt = <3000000>;
};

&mt_pmic_vmch_ldo_reg {
	regulator-max-microvolt = <3000000>;
};

&mt_pmic_vsim1_ldo_reg {
	regulator-min-microvolt = <1800000>;
	regulator-max-microvolt = <1800000>;
	regulator-boot-on;
};

&mt_pmic_vsim2_ldo_reg {
	regulator-min-microvolt = <1800000>;
	regulator-max-microvolt = <1800000>;
	/*regulator-boot-on;*/
};

&mt_pmic_vio28_ldo_reg {
	regulator-boot-on;
};

&mt_pmic_vcn33_bt_ldo_reg {
	regulator-min-microvolt = <3300000>;
	regulator-max-microvolt = <3300000>;
/*	regulator-boot-on;*/
};


&pio {
	pinctrl-names = "default";

	accdet_pins_default: accdetdefault {
	};

	aud_pins_mosi_on: mosion {
		pins_cmd_dat {
		pinmux = <MT8168_PIN_49_AUD_CLK_MOSI__FUNC_AUD_CLK_MOSI>,
			 <MT8168_PIN_50_AUD_SYNC_MOSI__FUNC_AUD_SYNC_MOSI>,
			 <MT8168_PIN_51_AUD_DAT_MOSI0__FUNC_AUD_DAT_MOSI0>,
			 <MT8168_PIN_52_AUD_DAT_MOSI1__FUNC_AUD_DAT_MOSI1>;
		drive-strength = <MTK_DRIVE_6mA>;
		};
	};

	aud_pins_mosi_off: mosioff {
		pins_cmd_dat {
		pinmux = <MT8168_PIN_49_AUD_CLK_MOSI__FUNC_GPIO49>,
			 <MT8168_PIN_50_AUD_SYNC_MOSI__FUNC_GPIO50>,
			 <MT8168_PIN_51_AUD_DAT_MOSI0__FUNC_GPIO51>,
			 <MT8168_PIN_52_AUD_DAT_MOSI1__FUNC_GPIO52>;
		input-enable;
		bias-pull-down;
		drive-strength = <MTK_DRIVE_2mA>;
		};
	};

	aud_pins_miso_on: misoon {
		pins_cmd_dat {
		pinmux = <MT8168_PIN_53_AUD_CLK_MISO__FUNC_AUD_CLK_MISO>,
			 <MT8168_PIN_54_AUD_SYNC_MISO__FUNC_AUD_SYNC_MISO>,
			 <MT8168_PIN_55_AUD_DAT_MISO0__FUNC_AUD_DAT_MISO0>,
			 <MT8168_PIN_56_AUD_DAT_MISO1__FUNC_AUD_DAT_MISO1>;
		drive-strength = <MTK_DRIVE_6mA>;
		};
	};

	aud_pins_miso_off: misooff {
		pins_cmd_dat {
		pinmux = <MT8168_PIN_53_AUD_CLK_MISO__FUNC_GPIO53>,
			 <MT8168_PIN_54_AUD_SYNC_MISO__FUNC_GPIO54>,
			 <MT8168_PIN_55_AUD_DAT_MISO0__FUNC_GPIO55>,
			 <MT8168_PIN_56_AUD_DAT_MISO1__FUNC_GPIO56>;
		input-enable;
		bias-pull-down;
		drive-strength = <MTK_DRIVE_2mA>;
		};
	};

	aud_pins_default: audiodefault {
	};

	aud_pins_dmic: audiodmic {
	};

	aud_pins_pcm: audiopcm {
	};

	aud_pins_i2s0: audioi2s0 {
	};

	aud_pins_i2s1: audioi2s1 {
	};

	aud_pins_i2s2: audioi2s2 {
	};

	aud_pins_i2s3: audioi2s3 {
	};

	aud_pins_tdm_out: audiotdmout {
	};

	aud_pins_tdm_in: audiotdmin {
	};

	camera_pins_default: camdefault {
	};

	camera_pins_cam0_rst0: cam0@0 {
		pins_cmd_dat {
			pinmux = <MT8168_PIN_27_SPI_CK__FUNC_GPIO27>;
			slew-rate = <1>; /*direction 0:in, 1:out*/
			output-low;
		};
	};

	camera_pins_cam0_rst1: cam0@1 {
		pins_cmd_dat {
			pinmux = <MT8168_PIN_27_SPI_CK__FUNC_GPIO27>;
			slew-rate = <1>;
			output-high;
		};
	};

	camera_pins_cam0_pnd0: cam0@2 {
		pins_cmd_dat {
			pinmux = <MT8168_PIN_26_SPI_CS__FUNC_GPIO26>;
			slew-rate = <1>;
			output-low;
		};
	};

	camera_pins_cam0_pnd1: cam0@3 {
		pins_cmd_dat {
			pinmux = <MT8168_PIN_26_SPI_CS__FUNC_GPIO26>;
			slew-rate = <1>;
			output-high;
		};
	};

	camera_pins_cam1_rst0: cam1@0 {
		pins_cmd_dat {
			pinmux = <MT8168_PIN_29_SPI_MO__FUNC_GPIO29>;
			slew-rate = <1>; /*direction 0:in, 1:out*/
			output-low;
		};
	};

	camera_pins_cam1_rst1: cam1@1 {
		pins_cmd_dat {
			pinmux = <MT8168_PIN_29_SPI_MO__FUNC_GPIO29>;
			slew-rate = <1>;
			output-high;
		};
	};

	camera_pins_cam1_pnd0: cam1@2 {
		pins_cmd_dat {
			pinmux = <MT8168_PIN_28_SPI_MI__FUNC_GPIO28>;
			slew-rate = <1>;
			output-low;
		};
	};

	camera_pins_cam1_pnd1: cam1@3 {
		pins_cmd_dat {
			pinmux = <MT8168_PIN_28_SPI_MI__FUNC_GPIO28>;
			slew-rate = <1>;
			output-high;
		};
	};

	camera_pins_cam0_mclk_on: camera_pins_cam0_mclk_on {
		pins_cmd_dat {
			pinmux = <MT8168_PIN_65_CMMCLK0__FUNC_CMMCLK0>;
		};
	};

	camera_pins_cam0_mclk_off: camera_pins_cam0_mclk_off {
		pins_cmd_dat {
			pinmux = <MT8168_PIN_65_CMMCLK0__FUNC_GPIO65>;
		};
	};

	camera_pins_cam1_mclk_on: camera_pins_cam1_mclk_on {
		pins_cmd_dat {
			pinmux = <MT8168_PIN_66_CMMCLK1__FUNC_CMMCLK1>;
		};
	};

	camera_pins_cam1_mclk_off: camera_pins_cam1_mclk_off {
		pins_cmd_dat {
			pinmux = <MT8168_PIN_66_CMMCLK1__FUNC_GPIO66>;
		};
	};

	consys_pins_default: consys_default {
	};

	CTP_pins_default: eint0default {
		pins_cmd_dat {
			pinmux = <MT8168_PIN_78_CMHSYNC__FUNC_GPIO78>;
			slew-rate = <0>;
			bias-disable;
		};
	};

	CTP_pins_eint_as_int: eint@0 {
		pins_cmd_dat {
			pinmux = <MT8168_PIN_78_CMHSYNC__FUNC_GPIO78>;
			slew-rate = <0>;
			bias-disable;
		};
	};

	CTP_pins_eint_output0: eintoutput0 {
		pins_cmd_dat {
			pinmux = <MT8168_PIN_78_CMHSYNC__FUNC_GPIO78>;
			slew-rate = <1>;
			output-low;
		};
	};

	CTP_pins_eint_output1: eintoutput1 {
		pins_cmd_dat {
			pinmux = <MT8168_PIN_78_CMHSYNC__FUNC_GPIO78>;
			slew-rate = <1>;
			output-high;
		};
	};

	CTP_pins_rst_output0: rstoutput0 {
		pins_cmd_dat {
			pinmux = <MT8168_PIN_79_CMVSYNC__FUNC_GPIO79>;
			slew-rate = <1>;
			output-low;
		};
	};

	CTP_pins_rst_output1: rstoutput1 {
		pins_cmd_dat {
			pinmux = <MT8168_PIN_79_CMVSYNC__FUNC_GPIO79>;
			slew-rate = <1>;
			output-high;
		};
	};

	ethernet_pins_default: ethernet {
	};

	gpslna_pins_init: gpslna@0 {
		pins_cmd_dat {
			pinmux = <MT8168_PIN_77_CMDAT9__FUNC_GPIO77>;
			slew-rate = <0>;
			bias-disable;
			output-low;
		};
	};

	gpslna_pins_oh: gpslna@1 {
		pins_cmd_dat {
			pinmux = <MT8168_PIN_77_CMDAT9__FUNC_GPIO77>;
			slew-rate = <1>;
			output-high;
		};
	};

	gpslna_pins_ol: gpslna@2 {
		pins_cmd_dat {
			pinmux = <MT8168_PIN_77_CMDAT9__FUNC_GPIO77>;
			slew-rate = <1>;
			output-low;
		};
	};

	i2c0_pins: i2c0 {
		pins_bus {
			pinmux = <MT8168_PIN_57_SDA0__FUNC_SDA0_0>,
				 <MT8168_PIN_58_SCL0__FUNC_SCL0_0>;
			bias-pull-up = <MTK_PUPD_SET_R1R0_00>;
		};
	};

	i2c0_pins_gpio: i2c0_gpio {
		pins_bus {
			pinmux = <MT8168_PIN_57_SDA0__FUNC_GPIO57>,
				 <MT8168_PIN_58_SCL0__FUNC_GPIO58>;
			bias-pull-up = <MTK_PUPD_SET_R1R0_00>;
		};
	};

	i2c1_pins: i2c1 {
		pins_bus {
			pinmux = <MT8168_PIN_59_SDA1__FUNC_SDA1_0>,
				 <MT8168_PIN_60_SCL1__FUNC_SCL1_0>;
			bias-pull-up = <MTK_PUPD_SET_R1R0_00>;
		};
	};

	i2c1_pins_gpio: i2c1_gpio {
		pins_bus {
			pinmux = <MT8168_PIN_59_SDA1__FUNC_GPIO59>,
				 <MT8168_PIN_60_SCL1__FUNC_GPIO60>;
			bias-pull-up = <MTK_PUPD_SET_R1R0_00>;
		};
	};

	i2c2_pins: i2c2 {
		pins_bus {
			pinmux = <MT8168_PIN_61_SDA2__FUNC_SDA2_0>,
				 <MT8168_PIN_62_SCL2__FUNC_SCL2_0>;
			bias-pull-up = <MTK_PUPD_SET_R1R0_00>;
		};
	};

	i2c2_pins_gpio: i2c2_gpio {
		pins_bus {
			pinmux = <MT8168_PIN_61_SDA2__FUNC_GPIO61>,
				 <MT8168_PIN_62_SCL2__FUNC_GPIO62>;
			bias-pull-up = <MTK_PUPD_SET_R1R0_00>;
		};
	};

	i2c3_pins: i2c3 {
		pins_bus {
			pinmux = <MT8168_PIN_63_SDA3__FUNC_SDA3_0>,
				 <MT8168_PIN_64_SCL3__FUNC_SCL3_0>;
//			bias-pull-up = <MTK_PUPD_SET_R1R0_00>;
//			bias-disable;
//			drive-strength = <MTK_DRIVE_6mA>;
			bias-pull-down;
		};
	};

	kpd_pins_default: kpddefault {
		pins_cols {
			pinmux = <MT8168_PIN_24_KPCOL0__FUNC_KPCOL0>,
				 <MT8168_PIN_25_KPCOL1__FUNC_KPCOL1>;
			input-enable;
			bias-pull-up = <MTK_PUPD_SET_R1R0_01>;
		};
	};

	mmc0_pins_default: mmc0default {
		pins_clk {
			pinmux = <MT8168_PIN_99_MSDC0_CLK__FUNC_MSDC0_CLK>;
			bias-pull-down;
		};

		pins_cmd_dat {
			pinmux = <MT8168_PIN_103_MSDC0_DAT0__FUNC_MSDC0_DAT0>,
				 <MT8168_PIN_102_MSDC0_DAT1__FUNC_MSDC0_DAT1>,
				 <MT8168_PIN_101_MSDC0_DAT2__FUNC_MSDC0_DAT2>,
				 <MT8168_PIN_100_MSDC0_DAT3__FUNC_MSDC0_DAT3>,
				 <MT8168_PIN_96_MSDC0_DAT4__FUNC_MSDC0_DAT4>,
				 <MT8168_PIN_95_MSDC0_DAT5__FUNC_MSDC0_DAT5>,
				 <MT8168_PIN_94_MSDC0_DAT6__FUNC_MSDC0_DAT6>,
				 <MT8168_PIN_93_MSDC0_DAT7__FUNC_MSDC0_DAT7>,
				 <MT8168_PIN_98_MSDC0_CMD__FUNC_MSDC0_CMD>;
			input-enable;
			bias-pull-up;
		};

		pins_rst {
			pinmux = <MT8168_PIN_97_MSDC0_RSTB__FUNC_MSDC0_RSTB>;
			bias-pull-up;
		};
	};

	mmc0_pins_uhs: mmc0 {
		pins_clk {
			pinmux = <MT8168_PIN_99_MSDC0_CLK__FUNC_MSDC0_CLK>;
			drive-strength = <MTK_DRIVE_6mA>;
			bias-pull-down = <MTK_PUPD_SET_R1R0_01>;
		};

		pins_cmd_dat {
			pinmux = <MT8168_PIN_103_MSDC0_DAT0__FUNC_MSDC0_DAT0>,
				 <MT8168_PIN_102_MSDC0_DAT1__FUNC_MSDC0_DAT1>,
				 <MT8168_PIN_101_MSDC0_DAT2__FUNC_MSDC0_DAT2>,
				 <MT8168_PIN_100_MSDC0_DAT3__FUNC_MSDC0_DAT3>,
				 <MT8168_PIN_96_MSDC0_DAT4__FUNC_MSDC0_DAT4>,
				 <MT8168_PIN_95_MSDC0_DAT5__FUNC_MSDC0_DAT5>,
				 <MT8168_PIN_94_MSDC0_DAT6__FUNC_MSDC0_DAT6>,
				 <MT8168_PIN_93_MSDC0_DAT7__FUNC_MSDC0_DAT7>,
				 <MT8168_PIN_98_MSDC0_CMD__FUNC_MSDC0_CMD>;
			input-enable;
			drive-strength = <MTK_DRIVE_6mA>;
			bias-pull-up = <MTK_PUPD_SET_R1R0_01>;
		};

		pins_ds {
			pinmux = <MT8168_PIN_104_MSDC0_DSL__FUNC_MSDC0_DSL>;
			drive-strength = <MTK_DRIVE_6mA>;
			bias-pull-down = <MTK_PUPD_SET_R1R0_10>;
		};

		pins_rst {
			pinmux = <MT8168_PIN_97_MSDC0_RSTB__FUNC_MSDC0_RSTB>;
			bias-pull-up;
		};
	};

	mmc1_pins_default: mmc1default {
		pins_clk {
			pinmux = <MT8168_PIN_88_MSDC1_CLK__FUNC_MSDC1_CLK>;
			drive-strength = <MTK_DRIVE_4mA>;
			bias-pull-down = <MTK_PUPD_SET_R1R0_10>;
		};

		pins_cmd_dat {
			pinmux = <MT8168_PIN_89_MSDC1_DAT0__FUNC_MSDC1_DAT0>,
				 <MT8168_PIN_90_MSDC1_DAT1__FUNC_MSDC1_DAT1>,
				 <MT8168_PIN_91_MSDC1_DAT2__FUNC_MSDC1_DAT2>,
				 <MT8168_PIN_92_MSDC1_DAT3__FUNC_MSDC1_DAT3>,
				 <MT8168_PIN_87_MSDC1_CMD__FUNC_MSDC1_CMD>;
			input-enable;
			drive-strength = <MTK_DRIVE_4mA>;
			bias-pull-up = <MTK_PUPD_SET_R1R0_01>;
		};

		pins_insert {
			pinmux = <MT8168_PIN_76_CMDAT8__FUNC_GPIO76>;
			bias-pull-up;
		};
	};

	mmc1_pins_uhs: mmc1 {
		pins_clk {
			pinmux = <MT8168_PIN_88_MSDC1_CLK__FUNC_MSDC1_CLK>;
			drive-strength = <MTK_DRIVE_6mA>;
			bias-pull-down = <MTK_PUPD_SET_R1R0_10>;
		};

		pins_cmd_dat {
			pinmux = <MT8168_PIN_89_MSDC1_DAT0__FUNC_MSDC1_DAT0>,
				 <MT8168_PIN_90_MSDC1_DAT1__FUNC_MSDC1_DAT1>,
				 <MT8168_PIN_91_MSDC1_DAT2__FUNC_MSDC1_DAT2>,
				 <MT8168_PIN_92_MSDC1_DAT3__FUNC_MSDC1_DAT3>,
				 <MT8168_PIN_87_MSDC1_CMD__FUNC_MSDC1_CMD>;
			input-enable;
			drive-strength = <MTK_DRIVE_6mA>;
			bias-pull-up = <MTK_PUPD_SET_R1R0_01>;
		};
	};

	usbid_pins_default: usbid_pins_default {
		pins_cmd_dat {
			pinmux = <MT8168_PIN_17_GPIO17__FUNC_GPIO17>;
			input-enable;
			slew-rate = <0>;
			bias-pull-up;
		};
	};
};

&spi {
	status = "disabled";
};

&ssusb {
	phys = <&u2port0 PHY_TYPE_USB2>;
	vusb33-supply = <&mt_pmic_vusb33_ldo_reg>;
	vbus-supply = <&usb_p0_vbus>;
	vbst_5v-supply = <&vbst_5v>;
	extcon = <&extcon_usb>;
	dr_mode = "otg";
	status="okay";
};

&touch {
	vtouch-supply = <&mt_pmic_vcn33_bt_ldo_reg>;
	tpd-resolution = <800 1280>;
	use-tpd-button = <0>;
	tpd-key-num = <3>;
	tpd-key-local= <139 172 158 0>;
	tpd-key-dim-local = <90 883 100 40 230 883
		100 40 370 883 100 40 0 0 0 0>;
	tpd-max-touch-num = <5>;
	tpd-filter-enable = <1>;
	tpd-filter-pixel-density = <124>;
	tpd-filter-custom-prameters = <0 0 0 0 0 0 0 0 0 0 0 0>;
	tpd-filter-custom-speed = <0 0 0>;
	pinctrl-names = "default", "state_eint_as_int",
		"state_eint_output0", "state_eint_output1",
		"state_rst_output0", "state_rst_output1";
	pinctrl-0 = <&CTP_pins_default>;
	pinctrl-1 = <&CTP_pins_eint_as_int>;
	pinctrl-2 = <&CTP_pins_eint_output0>;
	pinctrl-3 = <&CTP_pins_eint_output1>;
	pinctrl-4 = <&CTP_pins_rst_output0>;
	pinctrl-5 = <&CTP_pins_rst_output1>;
	status = "disabled";
};

&u3phy0 {
	status="okay";
};

&uart0 {
	status="okay";
};

&uart1 {
	status="disabled";
};

&led6 {
	maxlevel = <1023>;
};
